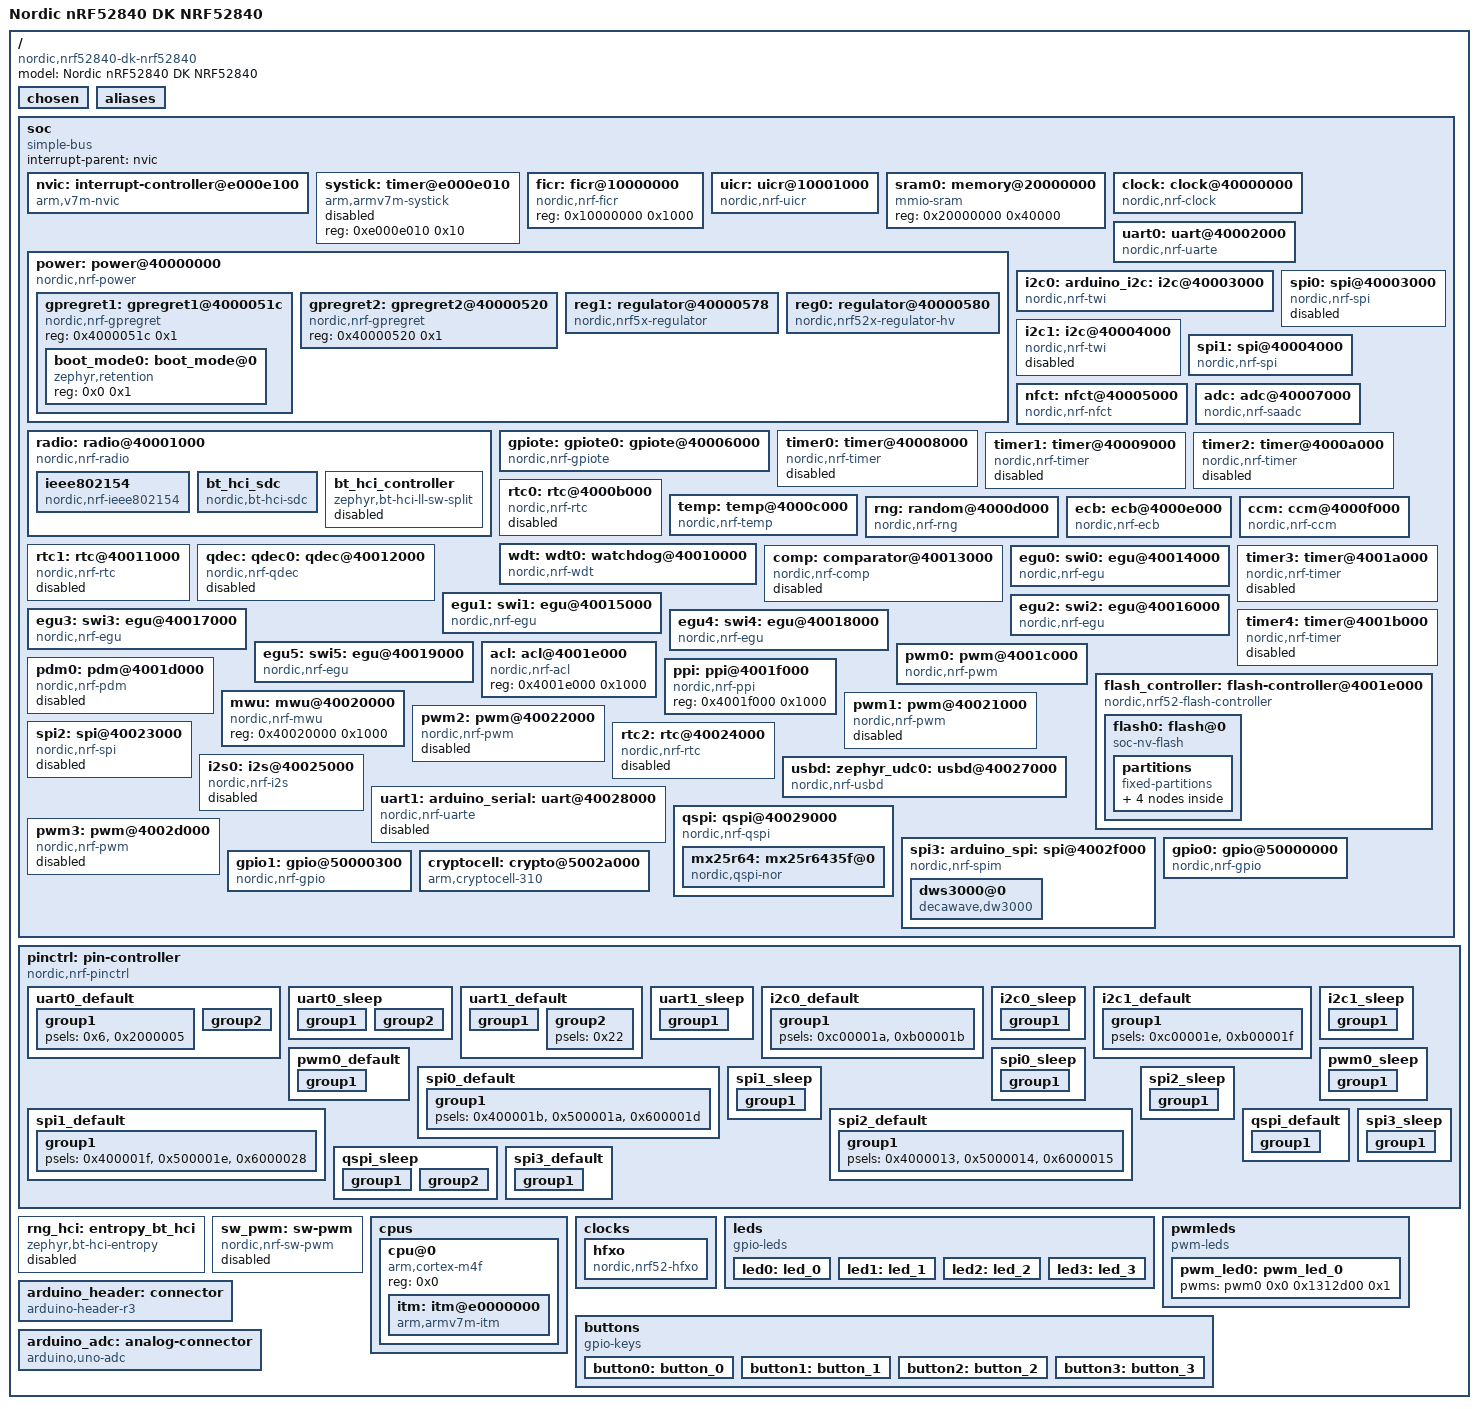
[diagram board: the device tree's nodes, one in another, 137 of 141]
/dts-v1/;

/* node '/' defined in zephyr\dts\common\skeleton.dtsi:9 */
/ {
	#address-cells = < 0x1 >;                   /* in zephyr\dts\common\skeleton.dtsi:10 */
	#size-cells = < 0x1 >;                      /* in zephyr\dts\common\skeleton.dtsi:11 */
	model = "Nordic nRF52840 DK NRF52840";      /* in zephyr\boards\nordic\nrf52840dk\nrf52840dk_nrf52840.dts:15 */
	compatible = "nordic,nrf52840-dk-nrf52840"; /* in zephyr\boards\nordic\nrf52840dk\nrf52840dk_nrf52840.dts:16 */

	/* node '/chosen' defined in zephyr\dts\common\skeleton.dtsi:13 */
	chosen {
		zephyr,bt-hci = &bt_hci_sdc;                 /* in zephyr\dts\arm\nordic\nrf52840.dtsi:14 */
		zephyr,entropy = &cryptocell;                /* in zephyr\dts\arm\nordic\nrf52840.dtsi:15 */
		zephyr,flash-controller = &flash_controller; /* in zephyr\dts\arm\nordic\nrf52840.dtsi:16 */
		zephyr,sram = &sram0;                        /* in zephyr\dts\vendor\nordic\nrf52840_partition.dtsi:9 */
		zephyr,flash = &flash0;                      /* in zephyr\dts\vendor\nordic\nrf52840_partition.dtsi:10 */
		zephyr,code-partition = &slot0_partition;    /* in zephyr\dts\vendor\nordic\nrf52840_partition.dtsi:11 */
		zephyr,console = &uart0;                     /* in zephyr\boards\nordic\nrf52840dk\nrf52840dk_nrf52840.dts:19 */
		zephyr,shell-uart = &uart0;                  /* in zephyr\boards\nordic\nrf52840dk\nrf52840dk_nrf52840.dts:20 */
		zephyr,uart-mcumgr = &uart0;                 /* in zephyr\boards\nordic\nrf52840dk\nrf52840dk_nrf52840.dts:21 */
		zephyr,bt-mon-uart = &uart0;                 /* in zephyr\boards\nordic\nrf52840dk\nrf52840dk_nrf52840.dts:22 */
		zephyr,bt-c2h-uart = &uart0;                 /* in zephyr\boards\nordic\nrf52840dk\nrf52840dk_nrf52840.dts:23 */
		zephyr,ieee802154 = &ieee802154;             /* in zephyr\boards\nordic\nrf52840dk\nrf52840dk_nrf52840.dts:24 */
		zephyr,boot-mode = &boot_mode0;              /* in zephyr\boards\nordic\nrf52840dk\nrf52840dk_nrf52840.dts:25 */
	};

	/* node '/aliases' defined in zephyr\dts\common\skeleton.dtsi:15 */
	aliases {
		led0 = &led0;               /* in zephyr\boards\nordic\nrf52840dk\nrf52840dk_nrf52840.dts:130 */
		led1 = &led1;               /* in zephyr\boards\nordic\nrf52840dk\nrf52840dk_nrf52840.dts:131 */
		led2 = &led2;               /* in zephyr\boards\nordic\nrf52840dk\nrf52840dk_nrf52840.dts:132 */
		led3 = &led3;               /* in zephyr\boards\nordic\nrf52840dk\nrf52840dk_nrf52840.dts:133 */
		pwm-led0 = &pwm_led0;       /* in zephyr\boards\nordic\nrf52840dk\nrf52840dk_nrf52840.dts:134 */
		sw0 = &button0;             /* in zephyr\boards\nordic\nrf52840dk\nrf52840dk_nrf52840.dts:135 */
		sw1 = &button1;             /* in zephyr\boards\nordic\nrf52840dk\nrf52840dk_nrf52840.dts:136 */
		sw2 = &button2;             /* in zephyr\boards\nordic\nrf52840dk\nrf52840dk_nrf52840.dts:137 */
		sw3 = &button3;             /* in zephyr\boards\nordic\nrf52840dk\nrf52840dk_nrf52840.dts:138 */
		mcuboot-button0 = &button0; /* in zephyr\boards\nordic\nrf52840dk\nrf52840dk_nrf52840.dts:139 */
		mcuboot-led0 = &led0;       /* in zephyr\boards\nordic\nrf52840dk\nrf52840dk_nrf52840.dts:140 */
		watchdog0 = &wdt0;          /* in zephyr\boards\nordic\nrf52840dk\nrf52840dk_nrf52840.dts:141 */
	};

	/* node '/soc' defined in zephyr\dts\arm\armv7-m.dtsi:6 */
	soc {
		#address-cells = < 0x1 >;     /* in zephyr\dts\arm\armv7-m.dtsi:7 */
		#size-cells = < 0x1 >;        /* in zephyr\dts\arm\armv7-m.dtsi:8 */
		interrupt-parent = < &nvic >; /* in zephyr\dts\arm\armv7-m.dtsi:10 */
		ranges;                       /* in zephyr\dts\arm\armv7-m.dtsi:11 */
		compatible = "simple-bus";    /* in zephyr\dts\arm\nordic\nrf52840_qiaa.dtsi:30 */

		/* node '/soc/interrupt-controller@e000e100' defined in zephyr\dts\arm\armv7-m.dtsi:13 */
		nvic: interrupt-controller@e000e100 {
			#address-cells = < 0x1 >;            /* in zephyr\dts\arm\armv7-m.dtsi:14 */
			compatible = "arm,v7m-nvic";         /* in zephyr\dts\arm\armv7-m.dtsi:15 */
			reg = < 0xe000e100 0xc00 >;          /* in zephyr\dts\arm\armv7-m.dtsi:16 */
			interrupt-controller;                /* in zephyr\dts\arm\armv7-m.dtsi:17 */
			#interrupt-cells = < 0x2 >;          /* in zephyr\dts\arm\armv7-m.dtsi:18 */
			arm,num-irq-priority-bits = < 0x3 >; /* in zephyr\dts\arm\nordic\nrf52840.dtsi:590 */
			phandle = < 0x1 >;                   /* in zephyr\dts\arm\armv7-m.dtsi:10 */
		};

		/* node '/soc/timer@e000e010' defined in zephyr\dts\arm\armv7-m.dtsi:21 */
		systick: timer@e000e010 {
			compatible = "arm,armv7m-systick"; /* in zephyr\dts\arm\armv7-m.dtsi:22 */
			reg = < 0xe000e010 0x10 >;         /* in zephyr\dts\arm\armv7-m.dtsi:23 */
			status = "disabled";               /* in zephyr\dts\arm\nordic\nrf52840.dtsi:595 */
		};

		/* node '/soc/ficr@10000000' defined in zephyr\dts\arm\nordic\nrf52840.dtsi:48 */
		ficr: ficr@10000000 {
			compatible = "nordic,nrf-ficr"; /* in zephyr\dts\arm\nordic\nrf52840.dtsi:49 */
			reg = < 0x10000000 0x1000 >;    /* in zephyr\dts\arm\nordic\nrf52840.dtsi:50 */
			#nordic,ficr-cells = < 0x1 >;   /* in zephyr\dts\arm\nordic\nrf52840.dtsi:51 */
			status = "okay";                /* in zephyr\dts\arm\nordic\nrf52840.dtsi:52 */
		};

		/* node '/soc/uicr@10001000' defined in zephyr\dts\arm\nordic\nrf52840.dtsi:55 */
		uicr: uicr@10001000 {
			compatible = "nordic,nrf-uicr";     /* in zephyr\dts\arm\nordic\nrf52840.dtsi:56 */
			reg = < 0x10001000 0x1000 >;        /* in zephyr\dts\arm\nordic\nrf52840.dtsi:57 */
			ranges = < 0x0 0x10001000 0x1000 >; /* in zephyr\dts\arm\nordic\nrf52840.dtsi:58 */
			status = "okay";                    /* in zephyr\dts\arm\nordic\nrf52840.dtsi:59 */
			#address-cells = < 0x1 >;           /* in zephyr\dts\arm\nordic\nrf52840.dtsi:60 */
			#size-cells = < 0x1 >;              /* in zephyr\dts\arm\nordic\nrf52840.dtsi:61 */
			gpio-as-nreset;                     /* in zephyr\boards\nordic\nrf52840dk\nrf52840dk_nrf52840.dts:158 */
		};

		/* node '/soc/memory@20000000' defined in zephyr\dts\arm\nordic\nrf52840.dtsi:64 */
		sram0: memory@20000000 {
			compatible = "mmio-sram";            /* in zephyr\dts\arm\nordic\nrf52840.dtsi:65 */
			#address-cells = < 0x1 >;            /* in zephyr\dts\arm\nordic\nrf52840.dtsi:66 */
			#size-cells = < 0x1 >;               /* in zephyr\dts\arm\nordic\nrf52840.dtsi:67 */
			reg = < 0x20000000 0x40000 >;        /* in zephyr\dts\arm\nordic\nrf52840_qiaa.dtsi:15 */
			ranges = < 0x0 0x20000000 0x40000 >; /* in zephyr\dts\arm\nordic\nrf52840_qiaa.dtsi:16 */
		};

		/* node '/soc/clock@40000000' defined in zephyr\dts\arm\nordic\nrf52840.dtsi:70 */
		clock: clock@40000000 {
			compatible = "nordic,nrf-clock"; /* in zephyr\dts\arm\nordic\nrf52840.dtsi:71 */
			reg = < 0x40000000 0x1000 >;     /* in zephyr\dts\arm\nordic\nrf52840.dtsi:72 */
			interrupts = < 0x0 0x1 >;        /* in zephyr\dts\arm\nordic\nrf52840.dtsi:73 */
			status = "okay";                 /* in zephyr\dts\arm\nordic\nrf52840.dtsi:74 */
		};

		/* node '/soc/power@40000000' defined in zephyr\dts\arm\nordic\nrf52840.dtsi:77 */
		power: power@40000000 {
			compatible = "nordic,nrf-power"; /* in zephyr\dts\arm\nordic\nrf52840.dtsi:78 */
			reg = < 0x40000000 0x1000 >;     /* in zephyr\dts\arm\nordic\nrf52840.dtsi:79 */
			interrupts = < 0x0 0x1 >;        /* in zephyr\dts\arm\nordic\nrf52840.dtsi:80 */
			status = "okay";                 /* in zephyr\dts\arm\nordic\nrf52840.dtsi:81 */
			#address-cells = < 0x1 >;        /* in zephyr\dts\arm\nordic\nrf52840.dtsi:82 */
			#size-cells = < 0x1 >;           /* in zephyr\dts\arm\nordic\nrf52840.dtsi:83 */

			/* node '/soc/power@40000000/gpregret1@4000051c' defined in zephyr\dts\arm\nordic\nrf52840.dtsi:85 */
			gpregret1: gpregret1@4000051c {
				#address-cells = < 0x1 >;           /* in zephyr\dts\arm\nordic\nrf52840.dtsi:86 */
				#size-cells = < 0x1 >;              /* in zephyr\dts\arm\nordic\nrf52840.dtsi:87 */
				compatible = "nordic,nrf-gpregret"; /* in zephyr\dts\arm\nordic\nrf52840.dtsi:88 */
				reg = < 0x4000051c 0x1 >;           /* in zephyr\dts\arm\nordic\nrf52840.dtsi:89 */
				status = "okay";                    /* in zephyr\boards\nordic\nrf52840dk\nrf52840dk_nrf52840.dts:294 */

				/* node '/soc/power@40000000/gpregret1@4000051c/boot_mode@0' defined in zephyr\boards\nordic\nrf52840dk\nrf52840dk_nrf52840.dts:296 */
				boot_mode0: boot_mode@0 {
					compatible = "zephyr,retention"; /* in zephyr\boards\nordic\nrf52840dk\nrf52840dk_nrf52840.dts:297 */
					status = "okay";                 /* in zephyr\boards\nordic\nrf52840dk\nrf52840dk_nrf52840.dts:298 */
					reg = < 0x0 0x1 >;               /* in zephyr\boards\nordic\nrf52840dk\nrf52840dk_nrf52840.dts:299 */
				};
			};

			/* node '/soc/power@40000000/gpregret2@40000520' defined in zephyr\dts\arm\nordic\nrf52840.dtsi:93 */
			gpregret2: gpregret2@40000520 {
				#address-cells = < 0x1 >;           /* in zephyr\dts\arm\nordic\nrf52840.dtsi:94 */
				#size-cells = < 0x1 >;              /* in zephyr\dts\arm\nordic\nrf52840.dtsi:95 */
				compatible = "nordic,nrf-gpregret"; /* in zephyr\dts\arm\nordic\nrf52840.dtsi:96 */
				reg = < 0x40000520 0x1 >;           /* in zephyr\dts\arm\nordic\nrf52840.dtsi:97 */
				status = "okay";                    /* in zephyr\dts\arm\nordic\nrf52840.dtsi:98 */
			};

			/* node '/soc/power@40000000/regulator@40000578' defined in zephyr\dts\arm\nordic\nrf52840.dtsi:101 */
			reg1: regulator@40000578 {
				compatible = "nordic,nrf5x-regulator"; /* in zephyr\dts\arm\nordic\nrf52840.dtsi:102 */
				reg = < 0x40000578 0x1 >;              /* in zephyr\dts\arm\nordic\nrf52840.dtsi:103 */
				regulator-name = "REG1";               /* in zephyr\dts\arm\nordic\nrf52840.dtsi:104 */
				regulator-initial-mode = < 0x1 >;      /* in zephyr\boards\nordic\nrf52840dk\nrf52840dk_nrf52840.dts:150 */
			};

			/* node '/soc/power@40000000/regulator@40000580' defined in zephyr\dts\arm\nordic\nrf52840_qiaa.dtsi:20 */
			reg0: regulator@40000580 {
				compatible = "nordic,nrf52x-regulator-hv"; /* in zephyr\dts\arm\nordic\nrf52840_qiaa.dtsi:21 */
				reg = < 0x40000580 0x1 >;                  /* in zephyr\dts\arm\nordic\nrf52840_qiaa.dtsi:22 */
				regulator-name = "REG0";                   /* in zephyr\dts\arm\nordic\nrf52840_qiaa.dtsi:23 */
				status = "okay";                           /* in zephyr\boards\nordic\nrf52840dk\nrf52840dk_nrf52840.dts:146 */
			};
		};

		/* node '/soc/radio@40001000' defined in zephyr\dts\arm\nordic\nrf52840.dtsi:109 */
		radio: radio@40001000 {
			compatible = "nordic,nrf-radio"; /* in zephyr\dts\arm\nordic\nrf52840.dtsi:110 */
			reg = < 0x40001000 0x1000 >;     /* in zephyr\dts\arm\nordic\nrf52840.dtsi:111 */
			interrupts = < 0x1 0x1 >;        /* in zephyr\dts\arm\nordic\nrf52840.dtsi:112 */
			status = "okay";                 /* in zephyr\dts\arm\nordic\nrf52840.dtsi:113 */
			ieee802154-supported;            /* in zephyr\dts\arm\nordic\nrf52840.dtsi:114 */
			ble-2mbps-supported;             /* in zephyr\dts\arm\nordic\nrf52840.dtsi:115 */
			ble-coded-phy-supported;         /* in zephyr\dts\arm\nordic\nrf52840.dtsi:116 */
			radio-tx-high-power-supported;   /* in zephyr\dts\arm\nordic\nrf52840.dtsi:117 */

			/* node '/soc/radio@40001000/ieee802154' defined in zephyr\dts\arm\nordic\nrf52840.dtsi:119 */
			ieee802154: ieee802154 {
				compatible = "nordic,nrf-ieee802154"; /* in zephyr\dts\arm\nordic\nrf52840.dtsi:120 */
				status = "okay";                      /* in zephyr\boards\nordic\nrf52840dk\nrf52840dk_nrf52840.dts:285 */
			};

			/* node '/soc/radio@40001000/bt_hci_sdc' defined in zephyr\dts\arm\nordic\nrf52840.dtsi:124 */
			bt_hci_sdc: bt_hci_sdc {
				compatible = "nordic,bt-hci-sdc"; /* in zephyr\dts\arm\nordic\nrf52840.dtsi:125 */
				status = "okay";                  /* in zephyr\dts\arm\nordic\nrf52840.dtsi:126 */
			};

			/* node '/soc/radio@40001000/bt_hci_controller' defined in zephyr\dts\arm\nordic\nrf52840.dtsi:128 */
			bt_hci_controller: bt_hci_controller {
				compatible = "zephyr,bt-hci-ll-sw-split"; /* in zephyr\dts\arm\nordic\nrf52840.dtsi:129 */
				status = "disabled";                      /* in zephyr\dts\arm\nordic\nrf52840.dtsi:130 */
			};
		};

		/* node '/soc/uart@40002000' defined in zephyr\dts\arm\nordic\nrf52840.dtsi:134 */
		uart0: uart@40002000 {
			reg = < 0x40002000 0x1000 >;     /* in zephyr\dts\arm\nordic\nrf52840.dtsi:138 */
			interrupts = < 0x2 0x1 >;        /* in zephyr\dts\arm\nordic\nrf52840.dtsi:139 */
			compatible = "nordic,nrf-uarte"; /* in zephyr\boards\nordic\nrf52840dk\nrf52840dk_nrf52840.dts:186 */
			status = "okay";                 /* in zephyr\boards\nordic\nrf52840dk\nrf52840dk_nrf52840.dts:187 */
			current-speed = < 0x1c200 >;     /* in zephyr\boards\nordic\nrf52840dk\nrf52840dk_nrf52840.dts:188 */
			pinctrl-0 = < &uart0_default >;  /* in zephyr\boards\nordic\nrf52840dk\nrf52840dk_nrf52840.dts:189 */
			pinctrl-1 = < &uart0_sleep >;    /* in zephyr\boards\nordic\nrf52840dk\nrf52840dk_nrf52840.dts:190 */
			pinctrl-names = "default",
			                "sleep";         /* in zephyr\boards\nordic\nrf52840dk\nrf52840dk_nrf52840.dts:191 */
		};

		/* node '/soc/i2c@40003000' defined in zephyr\dts\arm\nordic\nrf52840.dtsi:143 */
		i2c0: arduino_i2c: i2c@40003000 {
			#address-cells = < 0x1 >;       /* in zephyr\dts\arm\nordic\nrf52840.dtsi:152 */
			#size-cells = < 0x0 >;          /* in zephyr\dts\arm\nordic\nrf52840.dtsi:153 */
			reg = < 0x40003000 0x1000 >;    /* in zephyr\dts\arm\nordic\nrf52840.dtsi:154 */
			interrupts = < 0x3 0x1 >;       /* in zephyr\dts\arm\nordic\nrf52840.dtsi:155 */
			easydma-maxcnt-bits = < 0x10 >; /* in zephyr\dts\arm\nordic\nrf52840.dtsi:156 */
			zephyr,pm-device-runtime-auto;  /* in zephyr\dts\arm\nordic\nrf52840.dtsi:158 */
			compatible = "nordic,nrf-twi";  /* in zephyr\boards\nordic\nrf52840dk\nrf52840dk_nrf52840.dts:202 */
			status = "okay";                /* in zephyr\boards\nordic\nrf52840dk\nrf52840dk_nrf52840.dts:203 */
			pinctrl-0 = < &i2c0_default >;  /* in zephyr\boards\nordic\nrf52840dk\nrf52840dk_nrf52840.dts:204 */
			pinctrl-1 = < &i2c0_sleep >;    /* in zephyr\boards\nordic\nrf52840dk\nrf52840dk_nrf52840.dts:205 */
			pinctrl-names = "default",
			                "sleep";        /* in zephyr\boards\nordic\nrf52840dk\nrf52840dk_nrf52840.dts:206 */
		};

		/* node '/soc/spi@40003000' defined in zephyr\dts\arm\nordic\nrf52840.dtsi:161 */
		spi0: spi@40003000 {
			#address-cells = < 0x1 >;       /* in zephyr\dts\arm\nordic\nrf52840.dtsi:170 */
			#size-cells = < 0x0 >;          /* in zephyr\dts\arm\nordic\nrf52840.dtsi:171 */
			reg = < 0x40003000 0x1000 >;    /* in zephyr\dts\arm\nordic\nrf52840.dtsi:172 */
			interrupts = < 0x3 0x1 >;       /* in zephyr\dts\arm\nordic\nrf52840.dtsi:173 */
			max-frequency = < 0x7a1200 >;   /* in zephyr\dts\arm\nordic\nrf52840.dtsi:174 */
			easydma-maxcnt-bits = < 0x10 >; /* in zephyr\dts\arm\nordic\nrf52840.dtsi:175 */
			status = "disabled";            /* in zephyr\dts\arm\nordic\nrf52840.dtsi:176 */
			compatible = "nordic,nrf-spi";  /* in zephyr\boards\nordic\nrf52840dk\nrf52840dk_nrf52840.dts:226 */
			pinctrl-0 = < &spi0_default >;  /* in zephyr\boards\nordic\nrf52840dk\nrf52840dk_nrf52840.dts:229 */
			pinctrl-1 = < &spi0_sleep >;    /* in zephyr\boards\nordic\nrf52840dk\nrf52840dk_nrf52840.dts:230 */
			pinctrl-names = "default",
			                "sleep";        /* in zephyr\boards\nordic\nrf52840dk\nrf52840dk_nrf52840.dts:231 */
		};

		/* node '/soc/i2c@40004000' defined in zephyr\dts\arm\nordic\nrf52840.dtsi:179 */
		i2c1: i2c@40004000 {
			#address-cells = < 0x1 >;       /* in zephyr\dts\arm\nordic\nrf52840.dtsi:188 */
			#size-cells = < 0x0 >;          /* in zephyr\dts\arm\nordic\nrf52840.dtsi:189 */
			reg = < 0x40004000 0x1000 >;    /* in zephyr\dts\arm\nordic\nrf52840.dtsi:190 */
			interrupts = < 0x4 0x1 >;       /* in zephyr\dts\arm\nordic\nrf52840.dtsi:191 */
			easydma-maxcnt-bits = < 0x10 >; /* in zephyr\dts\arm\nordic\nrf52840.dtsi:192 */
			status = "disabled";            /* in zephyr\dts\arm\nordic\nrf52840.dtsi:193 */
			zephyr,pm-device-runtime-auto;  /* in zephyr\dts\arm\nordic\nrf52840.dtsi:194 */
			compatible = "nordic,nrf-twi";  /* in zephyr\boards\nordic\nrf52840dk\nrf52840dk_nrf52840.dts:210 */
			pinctrl-0 = < &i2c1_default >;  /* in zephyr\boards\nordic\nrf52840dk\nrf52840dk_nrf52840.dts:213 */
			pinctrl-1 = < &i2c1_sleep >;    /* in zephyr\boards\nordic\nrf52840dk\nrf52840dk_nrf52840.dts:214 */
			pinctrl-names = "default",
			                "sleep";        /* in zephyr\boards\nordic\nrf52840dk\nrf52840dk_nrf52840.dts:215 */
		};

		/* node '/soc/spi@40004000' defined in zephyr\dts\arm\nordic\nrf52840.dtsi:197 */
		spi1: spi@40004000 {
			#address-cells = < 0x1 >;       /* in zephyr\dts\arm\nordic\nrf52840.dtsi:206 */
			#size-cells = < 0x0 >;          /* in zephyr\dts\arm\nordic\nrf52840.dtsi:207 */
			reg = < 0x40004000 0x1000 >;    /* in zephyr\dts\arm\nordic\nrf52840.dtsi:208 */
			interrupts = < 0x4 0x1 >;       /* in zephyr\dts\arm\nordic\nrf52840.dtsi:209 */
			max-frequency = < 0x7a1200 >;   /* in zephyr\dts\arm\nordic\nrf52840.dtsi:210 */
			easydma-maxcnt-bits = < 0x10 >; /* in zephyr\dts\arm\nordic\nrf52840.dtsi:211 */
			compatible = "nordic,nrf-spi";  /* in zephyr\boards\nordic\nrf52840dk\nrf52840dk_nrf52840.dts:235 */
			status = "okay";                /* in zephyr\boards\nordic\nrf52840dk\nrf52840dk_nrf52840.dts:236 */
			pinctrl-0 = < &spi1_default >;  /* in zephyr\boards\nordic\nrf52840dk\nrf52840dk_nrf52840.dts:237 */
			pinctrl-1 = < &spi1_sleep >;    /* in zephyr\boards\nordic\nrf52840dk\nrf52840dk_nrf52840.dts:238 */
			pinctrl-names = "default",
			                "sleep";        /* in zephyr\boards\nordic\nrf52840dk\nrf52840dk_nrf52840.dts:239 */
		};

		/* node '/soc/nfct@40005000' defined in zephyr\dts\arm\nordic\nrf52840.dtsi:215 */
		nfct: nfct@40005000 {
			compatible = "nordic,nrf-nfct"; /* in zephyr\dts\arm\nordic\nrf52840.dtsi:216 */
			reg = < 0x40005000 0x1000 >;    /* in zephyr\dts\arm\nordic\nrf52840.dtsi:217 */
			interrupts = < 0x5 0x1 >;       /* in zephyr\dts\arm\nordic\nrf52840.dtsi:218 */
			status = "okay";                /* in zephyr\boards\nordic\nrf52840dk\nrf52840dk_nrf52840.dts:166 */
		};

		/* node '/soc/gpiote@40006000' defined in zephyr\dts\arm\nordic\nrf52840.dtsi:222 */
		gpiote: gpiote0: gpiote@40006000 {
			compatible = "nordic,nrf-gpiote"; /* in zephyr\dts\arm\nordic\nrf52840.dtsi:223 */
			reg = < 0x40006000 0x1000 >;      /* in zephyr\dts\arm\nordic\nrf52840.dtsi:224 */
			interrupts = < 0x6 0x5 >;         /* in zephyr\dts\arm\nordic\nrf52840.dtsi:225 */
			instance = < 0x0 >;               /* in zephyr\dts\arm\nordic\nrf52840.dtsi:227 */
			status = "okay";                  /* in zephyr\boards\nordic\nrf52840dk\nrf52840dk_nrf52840.dts:162 */
			phandle = < 0x17 >;               /* in zephyr\dts\arm\nordic\nrf52840.dtsi:564 */
		};

		/* node '/soc/adc@40007000' defined in zephyr\dts\arm\nordic\nrf52840.dtsi:230 */
		adc: adc@40007000 {
			compatible = "nordic,nrf-saadc"; /* in zephyr\dts\arm\nordic\nrf52840.dtsi:231 */
			reg = < 0x40007000 0x1000 >;     /* in zephyr\dts\arm\nordic\nrf52840.dtsi:232 */
			interrupts = < 0x7 0x1 >;        /* in zephyr\dts\arm\nordic\nrf52840.dtsi:233 */
			#io-channel-cells = < 0x1 >;     /* in zephyr\dts\arm\nordic\nrf52840.dtsi:235 */
			zephyr,pm-device-runtime-auto;   /* in zephyr\dts\arm\nordic\nrf52840.dtsi:236 */
			status = "okay";                 /* in zephyr\boards\nordic\nrf52840dk\nrf52840dk_nrf52840.dts:154 */
			phandle = < 0x1c >;              /* in zephyr\boards\nordic\nrf52840dk\nrf52840dk_nrf52840.dts:120 */
		};

		/* node '/soc/timer@40008000' defined in zephyr\dts\arm\nordic\nrf52840.dtsi:239 */
		timer0: timer@40008000 {
			compatible = "nordic,nrf-timer"; /* in zephyr\dts\arm\nordic\nrf52840.dtsi:240 */
			status = "disabled";             /* in zephyr\dts\arm\nordic\nrf52840.dtsi:241 */
			reg = < 0x40008000 0x1000 >;     /* in zephyr\dts\arm\nordic\nrf52840.dtsi:242 */
			cc-num = < 0x4 >;                /* in zephyr\dts\arm\nordic\nrf52840.dtsi:243 */
			max-bit-width = < 0x20 >;        /* in zephyr\dts\arm\nordic\nrf52840.dtsi:244 */
			interrupts = < 0x8 0x1 >;        /* in zephyr\dts\arm\nordic\nrf52840.dtsi:245 */
			prescaler = < 0x0 >;             /* in zephyr\dts\arm\nordic\nrf52840.dtsi:246 */
		};

		/* node '/soc/timer@40009000' defined in zephyr\dts\arm\nordic\nrf52840.dtsi:249 */
		timer1: timer@40009000 {
			compatible = "nordic,nrf-timer"; /* in zephyr\dts\arm\nordic\nrf52840.dtsi:250 */
			status = "disabled";             /* in zephyr\dts\arm\nordic\nrf52840.dtsi:251 */
			reg = < 0x40009000 0x1000 >;     /* in zephyr\dts\arm\nordic\nrf52840.dtsi:252 */
			cc-num = < 0x4 >;                /* in zephyr\dts\arm\nordic\nrf52840.dtsi:253 */
			max-bit-width = < 0x20 >;        /* in zephyr\dts\arm\nordic\nrf52840.dtsi:254 */
			interrupts = < 0x9 0x1 >;        /* in zephyr\dts\arm\nordic\nrf52840.dtsi:255 */
			prescaler = < 0x0 >;             /* in zephyr\dts\arm\nordic\nrf52840.dtsi:256 */
			phandle = < 0x18 >;              /* in zephyr\dts\vendor\nordic\nrf_common.dtsi:42 */
		};

		/* node '/soc/timer@4000a000' defined in zephyr\dts\arm\nordic\nrf52840.dtsi:259 */
		timer2: timer@4000a000 {
			compatible = "nordic,nrf-timer"; /* in zephyr\dts\arm\nordic\nrf52840.dtsi:260 */
			status = "disabled";             /* in zephyr\dts\arm\nordic\nrf52840.dtsi:261 */
			reg = < 0x4000a000 0x1000 >;     /* in zephyr\dts\arm\nordic\nrf52840.dtsi:262 */
			cc-num = < 0x4 >;                /* in zephyr\dts\arm\nordic\nrf52840.dtsi:263 */
			max-bit-width = < 0x20 >;        /* in zephyr\dts\arm\nordic\nrf52840.dtsi:264 */
			interrupts = < 0xa 0x1 >;        /* in zephyr\dts\arm\nordic\nrf52840.dtsi:265 */
			prescaler = < 0x0 >;             /* in zephyr\dts\arm\nordic\nrf52840.dtsi:266 */
		};

		/* node '/soc/rtc@4000b000' defined in zephyr\dts\arm\nordic\nrf52840.dtsi:269 */
		rtc0: rtc@4000b000 {
			compatible = "nordic,nrf-rtc"; /* in zephyr\dts\arm\nordic\nrf52840.dtsi:270 */
			reg = < 0x4000b000 0x1000 >;   /* in zephyr\dts\arm\nordic\nrf52840.dtsi:271 */
			cc-num = < 0x3 >;              /* in zephyr\dts\arm\nordic\nrf52840.dtsi:272 */
			interrupts = < 0xb 0x1 >;      /* in zephyr\dts\arm\nordic\nrf52840.dtsi:273 */
			status = "disabled";           /* in zephyr\dts\arm\nordic\nrf52840.dtsi:274 */
			clock-frequency = < 0x8000 >;  /* in zephyr\dts\arm\nordic\nrf52840.dtsi:275 */
			prescaler = < 0x1 >;           /* in zephyr\dts\arm\nordic\nrf52840.dtsi:276 */
		};

		/* node '/soc/temp@4000c000' defined in zephyr\dts\arm\nordic\nrf52840.dtsi:279 */
		temp: temp@4000c000 {
			compatible = "nordic,nrf-temp"; /* in zephyr\dts\arm\nordic\nrf52840.dtsi:280 */
			reg = < 0x4000c000 0x1000 >;    /* in zephyr\dts\arm\nordic\nrf52840.dtsi:281 */
			interrupts = < 0xc 0x1 >;       /* in zephyr\dts\arm\nordic\nrf52840.dtsi:282 */
			status = "okay";                /* in zephyr\dts\arm\nordic\nrf52840.dtsi:283 */
		};

		/* node '/soc/random@4000d000' defined in zephyr\dts\arm\nordic\nrf52840.dtsi:286 */
		rng: random@4000d000 {
			compatible = "nordic,nrf-rng"; /* in zephyr\dts\arm\nordic\nrf52840.dtsi:287 */
			reg = < 0x4000d000 0x1000 >;   /* in zephyr\dts\arm\nordic\nrf52840.dtsi:288 */
			interrupts = < 0xd 0x1 >;      /* in zephyr\dts\arm\nordic\nrf52840.dtsi:289 */
			status = "okay";               /* in zephyr\dts\arm\nordic\nrf52840.dtsi:290 */
		};

		/* node '/soc/ecb@4000e000' defined in zephyr\dts\arm\nordic\nrf52840.dtsi:293 */
		ecb: ecb@4000e000 {
			compatible = "nordic,nrf-ecb"; /* in zephyr\dts\arm\nordic\nrf52840.dtsi:294 */
			reg = < 0x4000e000 0x1000 >;   /* in zephyr\dts\arm\nordic\nrf52840.dtsi:295 */
			interrupts = < 0xe 0x1 >;      /* in zephyr\dts\arm\nordic\nrf52840.dtsi:296 */
			status = "okay";               /* in zephyr\dts\arm\nordic\nrf52840.dtsi:297 */
		};

		/* node '/soc/ccm@4000f000' defined in zephyr\dts\arm\nordic\nrf52840.dtsi:300 */
		ccm: ccm@4000f000 {
			compatible = "nordic,nrf-ccm"; /* in zephyr\dts\arm\nordic\nrf52840.dtsi:301 */
			reg = < 0x4000f000 0x1000 >;   /* in zephyr\dts\arm\nordic\nrf52840.dtsi:302 */
			interrupts = < 0xf 0x1 >;      /* in zephyr\dts\arm\nordic\nrf52840.dtsi:303 */
			length-field-length-8-bits;    /* in zephyr\dts\arm\nordic\nrf52840.dtsi:304 */
			status = "okay";               /* in zephyr\dts\arm\nordic\nrf52840.dtsi:305 */
		};

		/* node '/soc/watchdog@40010000' defined in zephyr\dts\arm\nordic\nrf52840.dtsi:308 */
		wdt: wdt0: watchdog@40010000 {
			compatible = "nordic,nrf-wdt"; /* in zephyr\dts\arm\nordic\nrf52840.dtsi:309 */
			reg = < 0x40010000 0x1000 >;   /* in zephyr\dts\arm\nordic\nrf52840.dtsi:310 */
			interrupts = < 0x10 0x1 >;     /* in zephyr\dts\arm\nordic\nrf52840.dtsi:311 */
			status = "okay";               /* in zephyr\dts\arm\nordic\nrf52840.dtsi:312 */
		};

		/* node '/soc/rtc@40011000' defined in zephyr\dts\arm\nordic\nrf52840.dtsi:315 */
		rtc1: rtc@40011000 {
			compatible = "nordic,nrf-rtc"; /* in zephyr\dts\arm\nordic\nrf52840.dtsi:316 */
			reg = < 0x40011000 0x1000 >;   /* in zephyr\dts\arm\nordic\nrf52840.dtsi:317 */
			cc-num = < 0x4 >;              /* in zephyr\dts\arm\nordic\nrf52840.dtsi:318 */
			interrupts = < 0x11 0x1 >;     /* in zephyr\dts\arm\nordic\nrf52840.dtsi:319 */
			status = "disabled";           /* in zephyr\dts\arm\nordic\nrf52840.dtsi:320 */
			clock-frequency = < 0x8000 >;  /* in zephyr\dts\arm\nordic\nrf52840.dtsi:321 */
			prescaler = < 0x1 >;           /* in zephyr\dts\arm\nordic\nrf52840.dtsi:322 */
		};

		/* node '/soc/qdec@40012000' defined in zephyr\dts\arm\nordic\nrf52840.dtsi:325 */
		qdec: qdec0: qdec@40012000 {
			compatible = "nordic,nrf-qdec"; /* in zephyr\dts\arm\nordic\nrf52840.dtsi:326 */
			reg = < 0x40012000 0x1000 >;    /* in zephyr\dts\arm\nordic\nrf52840.dtsi:327 */
			interrupts = < 0x12 0x1 >;      /* in zephyr\dts\arm\nordic\nrf52840.dtsi:328 */
			status = "disabled";            /* in zephyr\dts\arm\nordic\nrf52840.dtsi:329 */
		};

		/* node '/soc/comparator@40013000' defined in zephyr\dts\arm\nordic\nrf52840.dtsi:332 */
		comp: comparator@40013000 {
			compatible = "nordic,nrf-comp"; /* in zephyr\dts\arm\nordic\nrf52840.dtsi:337 */
			reg = < 0x40013000 0x1000 >;    /* in zephyr\dts\arm\nordic\nrf52840.dtsi:338 */
			interrupts = < 0x13 0x1 >;      /* in zephyr\dts\arm\nordic\nrf52840.dtsi:339 */
			status = "disabled";            /* in zephyr\dts\arm\nordic\nrf52840.dtsi:340 */
		};

		/* node '/soc/egu@40014000' defined in zephyr\dts\arm\nordic\nrf52840.dtsi:343 */
		egu0: swi0: egu@40014000 {
			compatible = "nordic,nrf-egu",
			             "nordic,nrf-swi"; /* in zephyr\dts\arm\nordic\nrf52840.dtsi:344 */
			reg = < 0x40014000 0x1000 >;   /* in zephyr\dts\arm\nordic\nrf52840.dtsi:345 */
			interrupts = < 0x14 0x1 >;     /* in zephyr\dts\arm\nordic\nrf52840.dtsi:346 */
			status = "okay";               /* in zephyr\dts\arm\nordic\nrf52840.dtsi:347 */
		};

		/* node '/soc/egu@40015000' defined in zephyr\dts\arm\nordic\nrf52840.dtsi:350 */
		egu1: swi1: egu@40015000 {
			compatible = "nordic,nrf-egu",
			             "nordic,nrf-swi"; /* in zephyr\dts\arm\nordic\nrf52840.dtsi:351 */
			reg = < 0x40015000 0x1000 >;   /* in zephyr\dts\arm\nordic\nrf52840.dtsi:352 */
			interrupts = < 0x15 0x1 >;     /* in zephyr\dts\arm\nordic\nrf52840.dtsi:353 */
			status = "okay";               /* in zephyr\dts\arm\nordic\nrf52840.dtsi:354 */
		};

		/* node '/soc/egu@40016000' defined in zephyr\dts\arm\nordic\nrf52840.dtsi:357 */
		egu2: swi2: egu@40016000 {
			compatible = "nordic,nrf-egu",
			             "nordic,nrf-swi"; /* in zephyr\dts\arm\nordic\nrf52840.dtsi:358 */
			reg = < 0x40016000 0x1000 >;   /* in zephyr\dts\arm\nordic\nrf52840.dtsi:359 */
			interrupts = < 0x16 0x1 >;     /* in zephyr\dts\arm\nordic\nrf52840.dtsi:360 */
			status = "okay";               /* in zephyr\dts\arm\nordic\nrf52840.dtsi:361 */
		};

		/* node '/soc/egu@40017000' defined in zephyr\dts\arm\nordic\nrf52840.dtsi:364 */
		egu3: swi3: egu@40017000 {
			compatible = "nordic,nrf-egu",
			             "nordic,nrf-swi"; /* in zephyr\dts\arm\nordic\nrf52840.dtsi:365 */
			reg = < 0x40017000 0x1000 >;   /* in zephyr\dts\arm\nordic\nrf52840.dtsi:366 */
			interrupts = < 0x17 0x1 >;     /* in zephyr\dts\arm\nordic\nrf52840.dtsi:367 */
			status = "okay";               /* in zephyr\dts\arm\nordic\nrf52840.dtsi:368 */
		};

		/* node '/soc/egu@40018000' defined in zephyr\dts\arm\nordic\nrf52840.dtsi:371 */
		egu4: swi4: egu@40018000 {
			compatible = "nordic,nrf-egu",
			             "nordic,nrf-swi"; /* in zephyr\dts\arm\nordic\nrf52840.dtsi:372 */
			reg = < 0x40018000 0x1000 >;   /* in zephyr\dts\arm\nordic\nrf52840.dtsi:373 */
			interrupts = < 0x18 0x1 >;     /* in zephyr\dts\arm\nordic\nrf52840.dtsi:374 */
			status = "okay";               /* in zephyr\dts\arm\nordic\nrf52840.dtsi:375 */
		};

		/* node '/soc/egu@40019000' defined in zephyr\dts\arm\nordic\nrf52840.dtsi:378 */
		egu5: swi5: egu@40019000 {
			compatible = "nordic,nrf-egu",
			             "nordic,nrf-swi"; /* in zephyr\dts\arm\nordic\nrf52840.dtsi:379 */
			reg = < 0x40019000 0x1000 >;   /* in zephyr\dts\arm\nordic\nrf52840.dtsi:380 */
			interrupts = < 0x19 0x1 >;     /* in zephyr\dts\arm\nordic\nrf52840.dtsi:381 */
			status = "okay";               /* in zephyr\dts\arm\nordic\nrf52840.dtsi:382 */
		};

		/* node '/soc/timer@4001a000' defined in zephyr\dts\arm\nordic\nrf52840.dtsi:385 */
		timer3: timer@4001a000 {
			compatible = "nordic,nrf-timer"; /* in zephyr\dts\arm\nordic\nrf52840.dtsi:386 */
			status = "disabled";             /* in zephyr\dts\arm\nordic\nrf52840.dtsi:387 */
			reg = < 0x4001a000 0x1000 >;     /* in zephyr\dts\arm\nordic\nrf52840.dtsi:388 */
			cc-num = < 0x6 >;                /* in zephyr\dts\arm\nordic\nrf52840.dtsi:389 */
			max-bit-width = < 0x20 >;        /* in zephyr\dts\arm\nordic\nrf52840.dtsi:390 */
			interrupts = < 0x1a 0x1 >;       /* in zephyr\dts\arm\nordic\nrf52840.dtsi:391 */
			prescaler = < 0x0 >;             /* in zephyr\dts\arm\nordic\nrf52840.dtsi:392 */
		};

		/* node '/soc/timer@4001b000' defined in zephyr\dts\arm\nordic\nrf52840.dtsi:395 */
		timer4: timer@4001b000 {
			compatible = "nordic,nrf-timer"; /* in zephyr\dts\arm\nordic\nrf52840.dtsi:396 */
			status = "disabled";             /* in zephyr\dts\arm\nordic\nrf52840.dtsi:397 */
			reg = < 0x4001b000 0x1000 >;     /* in zephyr\dts\arm\nordic\nrf52840.dtsi:398 */
			cc-num = < 0x6 >;                /* in zephyr\dts\arm\nordic\nrf52840.dtsi:399 */
			max-bit-width = < 0x20 >;        /* in zephyr\dts\arm\nordic\nrf52840.dtsi:400 */
			interrupts = < 0x1b 0x1 >;       /* in zephyr\dts\arm\nordic\nrf52840.dtsi:401 */
			prescaler = < 0x0 >;             /* in zephyr\dts\arm\nordic\nrf52840.dtsi:402 */
		};

		/* node '/soc/pwm@4001c000' defined in zephyr\dts\arm\nordic\nrf52840.dtsi:405 */
		pwm0: pwm@4001c000 {
			compatible = "nordic,nrf-pwm"; /* in zephyr\dts\arm\nordic\nrf52840.dtsi:406 */
			reg = < 0x4001c000 0x1000 >;   /* in zephyr\dts\arm\nordic\nrf52840.dtsi:407 */
			interrupts = < 0x1c 0x1 >;     /* in zephyr\dts\arm\nordic\nrf52840.dtsi:408 */
			#pwm-cells = < 0x3 >;          /* in zephyr\dts\arm\nordic\nrf52840.dtsi:410 */
			status = "okay";               /* in zephyr\boards\nordic\nrf52840dk\nrf52840dk_nrf52840.dts:219 */
			pinctrl-0 = < &pwm0_default >; /* in zephyr\boards\nordic\nrf52840dk\nrf52840dk_nrf52840.dts:220 */
			pinctrl-1 = < &pwm0_sleep >;   /* in zephyr\boards\nordic\nrf52840dk\nrf52840dk_nrf52840.dts:221 */
			pinctrl-names = "default",
			                "sleep";       /* in zephyr\boards\nordic\nrf52840dk\nrf52840dk_nrf52840.dts:222 */
			phandle = < 0x1a >;            /* in zephyr\boards\nordic\nrf52840dk\nrf52840dk_nrf52840.dts:56 */
		};

		/* node '/soc/pdm@4001d000' defined in zephyr\dts\arm\nordic\nrf52840.dtsi:413 */
		pdm0: pdm@4001d000 {
			compatible = "nordic,nrf-pdm"; /* in zephyr\dts\arm\nordic\nrf52840.dtsi:414 */
			reg = < 0x4001d000 0x1000 >;   /* in zephyr\dts\arm\nordic\nrf52840.dtsi:415 */
			interrupts = < 0x1d 0x1 >;     /* in zephyr\dts\arm\nordic\nrf52840.dtsi:416 */
			status = "disabled";           /* in zephyr\dts\arm\nordic\nrf52840.dtsi:417 */
		};

		/* node '/soc/acl@4001e000' defined in zephyr\dts\arm\nordic\nrf52840.dtsi:420 */
		acl: acl@4001e000 {
			compatible = "nordic,nrf-acl"; /* in zephyr\dts\arm\nordic\nrf52840.dtsi:421 */
			reg = < 0x4001e000 0x1000 >;   /* in zephyr\dts\arm\nordic\nrf52840.dtsi:422 */
			status = "okay";               /* in zephyr\dts\arm\nordic\nrf52840.dtsi:423 */
		};

		/* node '/soc/flash-controller@4001e000' defined in zephyr\dts\arm\nordic\nrf52840.dtsi:426 */
		flash_controller: flash-controller@4001e000 {
			compatible = "nordic,nrf52-flash-controller"; /* in zephyr\dts\arm\nordic\nrf52840.dtsi:427 */
			reg = < 0x4001e000 0x1000 >;                  /* in zephyr\dts\arm\nordic\nrf52840.dtsi:428 */
			partial-erase;                                /* in zephyr\dts\arm\nordic\nrf52840.dtsi:429 */
			#address-cells = < 0x1 >;                     /* in zephyr\dts\arm\nordic\nrf52840.dtsi:431 */
			#size-cells = < 0x1 >;                        /* in zephyr\dts\arm\nordic\nrf52840.dtsi:432 */

			/* node '/soc/flash-controller@4001e000/flash@0' defined in zephyr\dts\arm\nordic\nrf52840.dtsi:434 */
			flash0: flash@0 {
				compatible = "soc-nv-flash";   /* in zephyr\dts\arm\nordic\nrf52840.dtsi:435 */
				erase-block-size = < 0x1000 >; /* in zephyr\dts\arm\nordic\nrf52840.dtsi:436 */
				write-block-size = < 0x4 >;    /* in zephyr\dts\arm\nordic\nrf52840.dtsi:437 */
				reg = < 0x0 0x100000 >;        /* in zephyr\dts\arm\nordic\nrf52840_qiaa.dtsi:11 */

				/* node '/soc/flash-controller@4001e000/flash@0/partitions' defined in zephyr\dts\vendor\nordic\nrf52840_partition.dtsi:16 */
				partitions {
					compatible = "fixed-partitions"; /* in zephyr\dts\vendor\nordic\nrf52840_partition.dtsi:17 */
					#address-cells = < 0x1 >;        /* in zephyr\dts\vendor\nordic\nrf52840_partition.dtsi:18 */
					#size-cells = < 0x1 >;           /* in zephyr\dts\vendor\nordic\nrf52840_partition.dtsi:19 */

					/* node '/soc/flash-controller@4001e000/flash@0/partitions/partition@0' defined in zephyr\dts\vendor\nordic\nrf52840_partition.dtsi:21 */
					boot_partition: partition@0 {
						label = "mcuboot";    /* in zephyr\dts\vendor\nordic\nrf52840_partition.dtsi:22 */
						reg = < 0x0 0xc000 >; /* in zephyr\dts\vendor\nordic\nrf52840_partition.dtsi:23 */
					};

					/* node '/soc/flash-controller@4001e000/flash@0/partitions/partition@c000' defined in zephyr\dts\vendor\nordic\nrf52840_partition.dtsi:26 */
					slot0_partition: partition@c000 {
						label = "image-0";        /* in zephyr\dts\vendor\nordic\nrf52840_partition.dtsi:27 */
						reg = < 0xc000 0x76000 >; /* in zephyr\dts\vendor\nordic\nrf52840_partition.dtsi:28 */
					};

					/* node '/soc/flash-controller@4001e000/flash@0/partitions/partition@82000' defined in zephyr\dts\vendor\nordic\nrf52840_partition.dtsi:31 */
					slot1_partition: partition@82000 {
						label = "image-1";         /* in zephyr\dts\vendor\nordic\nrf52840_partition.dtsi:32 */
						reg = < 0x82000 0x76000 >; /* in zephyr\dts\vendor\nordic\nrf52840_partition.dtsi:33 */
					};

					/* node '/soc/flash-controller@4001e000/flash@0/partitions/partition@f8000' defined in zephyr\dts\vendor\nordic\nrf52840_partition.dtsi:45 */
					storage_partition: partition@f8000 {
						label = "storage";        /* in zephyr\dts\vendor\nordic\nrf52840_partition.dtsi:46 */
						reg = < 0xf8000 0x8000 >; /* in zephyr\dts\vendor\nordic\nrf52840_partition.dtsi:47 */
					};
				};
			};
		};

		/* node '/soc/ppi@4001f000' defined in zephyr\dts\arm\nordic\nrf52840.dtsi:441 */
		ppi: ppi@4001f000 {
			compatible = "nordic,nrf-ppi"; /* in zephyr\dts\arm\nordic\nrf52840.dtsi:442 */
			reg = < 0x4001f000 0x1000 >;   /* in zephyr\dts\arm\nordic\nrf52840.dtsi:443 */
			status = "okay";               /* in zephyr\dts\arm\nordic\nrf52840.dtsi:444 */
		};

		/* node '/soc/mwu@40020000' defined in zephyr\dts\arm\nordic\nrf52840.dtsi:447 */
		mwu: mwu@40020000 {
			compatible = "nordic,nrf-mwu"; /* in zephyr\dts\arm\nordic\nrf52840.dtsi:448 */
			reg = < 0x40020000 0x1000 >;   /* in zephyr\dts\arm\nordic\nrf52840.dtsi:449 */
			status = "okay";               /* in zephyr\dts\arm\nordic\nrf52840.dtsi:450 */
		};

		/* node '/soc/pwm@40021000' defined in zephyr\dts\arm\nordic\nrf52840.dtsi:453 */
		pwm1: pwm@40021000 {
			compatible = "nordic,nrf-pwm"; /* in zephyr\dts\arm\nordic\nrf52840.dtsi:454 */
			reg = < 0x40021000 0x1000 >;   /* in zephyr\dts\arm\nordic\nrf52840.dtsi:455 */
			interrupts = < 0x21 0x1 >;     /* in zephyr\dts\arm\nordic\nrf52840.dtsi:456 */
			status = "disabled";           /* in zephyr\dts\arm\nordic\nrf52840.dtsi:457 */
			#pwm-cells = < 0x3 >;          /* in zephyr\dts\arm\nordic\nrf52840.dtsi:458 */
		};

		/* node '/soc/pwm@40022000' defined in zephyr\dts\arm\nordic\nrf52840.dtsi:461 */
		pwm2: pwm@40022000 {
			compatible = "nordic,nrf-pwm"; /* in zephyr\dts\arm\nordic\nrf52840.dtsi:462 */
			reg = < 0x40022000 0x1000 >;   /* in zephyr\dts\arm\nordic\nrf52840.dtsi:463 */
			interrupts = < 0x22 0x1 >;     /* in zephyr\dts\arm\nordic\nrf52840.dtsi:464 */
			status = "disabled";           /* in zephyr\dts\arm\nordic\nrf52840.dtsi:465 */
			#pwm-cells = < 0x3 >;          /* in zephyr\dts\arm\nordic\nrf52840.dtsi:466 */
		};

		/* node '/soc/spi@40023000' defined in zephyr\dts\arm\nordic\nrf52840.dtsi:469 */
		spi2: spi@40023000 {
			#address-cells = < 0x1 >;       /* in zephyr\dts\arm\nordic\nrf52840.dtsi:478 */
			#size-cells = < 0x0 >;          /* in zephyr\dts\arm\nordic\nrf52840.dtsi:479 */
			reg = < 0x40023000 0x1000 >;    /* in zephyr\dts\arm\nordic\nrf52840.dtsi:480 */
			interrupts = < 0x23 0x1 >;      /* in zephyr\dts\arm\nordic\nrf52840.dtsi:481 */
			max-frequency = < 0x7a1200 >;   /* in zephyr\dts\arm\nordic\nrf52840.dtsi:482 */
			easydma-maxcnt-bits = < 0x10 >; /* in zephyr\dts\arm\nordic\nrf52840.dtsi:483 */
			compatible = "nordic,nrf-spi";  /* in zephyr\boards\nordic\nrf52840dk\nrf52840dk_nrf52840.dts:243 */
			status = "disabled";            /* in zephyr\boards\nordic\nrf52840dk\nrf52840dk_nrf52840.dts:244 */
			pinctrl-0 = < &spi2_default >;  /* in zephyr\boards\nordic\nrf52840dk\nrf52840dk_nrf52840.dts:245 */
			pinctrl-1 = < &spi2_sleep >;    /* in zephyr\boards\nordic\nrf52840dk\nrf52840dk_nrf52840.dts:246 */
			pinctrl-names = "default",
			                "sleep";        /* in zephyr\boards\nordic\nrf52840dk\nrf52840dk_nrf52840.dts:247 */
		};

		/* node '/soc/rtc@40024000' defined in zephyr\dts\arm\nordic\nrf52840.dtsi:487 */
		rtc2: rtc@40024000 {
			compatible = "nordic,nrf-rtc"; /* in zephyr\dts\arm\nordic\nrf52840.dtsi:488 */
			reg = < 0x40024000 0x1000 >;   /* in zephyr\dts\arm\nordic\nrf52840.dtsi:489 */
			cc-num = < 0x4 >;              /* in zephyr\dts\arm\nordic\nrf52840.dtsi:490 */
			interrupts = < 0x24 0x1 >;     /* in zephyr\dts\arm\nordic\nrf52840.dtsi:491 */
			status = "disabled";           /* in zephyr\dts\arm\nordic\nrf52840.dtsi:492 */
			clock-frequency = < 0x8000 >;  /* in zephyr\dts\arm\nordic\nrf52840.dtsi:493 */
			prescaler = < 0x1 >;           /* in zephyr\dts\arm\nordic\nrf52840.dtsi:494 */
		};

		/* node '/soc/i2s@40025000' defined in zephyr\dts\arm\nordic\nrf52840.dtsi:497 */
		i2s0: i2s@40025000 {
			compatible = "nordic,nrf-i2s"; /* in zephyr\dts\arm\nordic\nrf52840.dtsi:498 */
			#address-cells = < 0x1 >;      /* in zephyr\dts\arm\nordic\nrf52840.dtsi:499 */
			#size-cells = < 0x0 >;         /* in zephyr\dts\arm\nordic\nrf52840.dtsi:500 */
			reg = < 0x40025000 0x1000 >;   /* in zephyr\dts\arm\nordic\nrf52840.dtsi:501 */
			interrupts = < 0x25 0x1 >;     /* in zephyr\dts\arm\nordic\nrf52840.dtsi:502 */
			status = "disabled";           /* in zephyr\dts\arm\nordic\nrf52840.dtsi:503 */
		};

		/* node '/soc/usbd@40027000' defined in zephyr\dts\arm\nordic\nrf52840.dtsi:506 */
		usbd: zephyr_udc0: usbd@40027000 {
			reg = < 0x40027000 0x1000 >;    /* in zephyr\dts\arm\nordic\nrf52840.dtsi:508 */
			interrupts = < 0x27 0x1 >;      /* in zephyr\dts\arm\nordic\nrf52840.dtsi:509 */
			num-bidir-endpoints = < 0x1 >;  /* in zephyr\dts\arm\nordic\nrf52840.dtsi:510 */
			num-in-endpoints = < 0x7 >;     /* in zephyr\dts\arm\nordic\nrf52840.dtsi:511 */
			num-out-endpoints = < 0x7 >;    /* in zephyr\dts\arm\nordic\nrf52840.dtsi:512 */
			num-isoin-endpoints = < 0x1 >;  /* in zephyr\dts\arm\nordic\nrf52840.dtsi:513 */
			num-isoout-endpoints = < 0x1 >; /* in zephyr\dts\arm\nordic\nrf52840.dtsi:514 */
			compatible = "nordic,nrf-usbd"; /* in zephyr\boards\nordic\nrf52840dk\nrf52840dk_nrf52840.dts:289 */
			status = "okay";                /* in zephyr\boards\nordic\nrf52840dk\nrf52840dk_nrf52840.dts:290 */
		};

		/* node '/soc/uart@40028000' defined in zephyr\dts\arm\nordic\nrf52840.dtsi:518 */
		uart1: arduino_serial: uart@40028000 {
			compatible = "nordic,nrf-uarte"; /* in zephyr\dts\arm\nordic\nrf52840.dtsi:519 */
			reg = < 0x40028000 0x1000 >;     /* in zephyr\dts\arm\nordic\nrf52840.dtsi:520 */
			interrupts = < 0x28 0x1 >;       /* in zephyr\dts\arm\nordic\nrf52840.dtsi:521 */
			current-speed = < 0x1c200 >;     /* in zephyr\boards\nordic\nrf52840dk\nrf52840dk_nrf52840.dts:195 */
			pinctrl-0 = < &uart1_default >;  /* in zephyr\boards\nordic\nrf52840dk\nrf52840dk_nrf52840.dts:196 */
			pinctrl-1 = < &uart1_sleep >;    /* in zephyr\boards\nordic\nrf52840dk\nrf52840dk_nrf52840.dts:197 */
			pinctrl-names = "default",
			                "sleep";         /* in zephyr\boards\nordic\nrf52840dk\nrf52840dk_nrf52840.dts:198 */
			status = "disabled";             /* in ..\..\spl\zephyr-dw3000-examples\dw3000-decadriver\zephyr\boards\shields\qorvo_dws3000\boards\nrf52840dk_nrf52840.overlay:6 */
		};

		/* node '/soc/qspi@40029000' defined in zephyr\dts\arm\nordic\nrf52840.dtsi:525 */
		qspi: qspi@40029000 {
			compatible = "nordic,nrf-qspi"; /* in zephyr\dts\arm\nordic\nrf52840.dtsi:526 */
			#address-cells = < 0x1 >;       /* in zephyr\dts\arm\nordic\nrf52840.dtsi:527 */
			#size-cells = < 0x0 >;          /* in zephyr\dts\arm\nordic\nrf52840.dtsi:528 */
			reg = < 0x40029000 0x1000 >,
			      < 0x12000000 0x8000000 >; /* in zephyr\dts\arm\nordic\nrf52840.dtsi:529 */
			reg-names = "qspi",
			            "qspi_mm";          /* in zephyr\dts\arm\nordic\nrf52840.dtsi:530 */
			interrupts = < 0x29 0x1 >;      /* in zephyr\dts\arm\nordic\nrf52840.dtsi:531 */
			status = "okay";                /* in zephyr\boards\nordic\nrf52840dk\nrf52840dk_nrf52840.dts:251 */
			pinctrl-0 = < &qspi_default >;  /* in zephyr\boards\nordic\nrf52840dk\nrf52840dk_nrf52840.dts:252 */
			pinctrl-1 = < &qspi_sleep >;    /* in zephyr\boards\nordic\nrf52840dk\nrf52840dk_nrf52840.dts:253 */
			pinctrl-names = "default",
			                "sleep";        /* in zephyr\boards\nordic\nrf52840dk\nrf52840dk_nrf52840.dts:254 */

			/* node '/soc/qspi@40029000/mx25r6435f@0' defined in zephyr\boards\nordic\nrf52840dk\nrf52840dk_nrf52840.dts:256 */
			mx25r64: mx25r6435f@0 {
				compatible = "nordic,qspi-nor";                                                               /* in zephyr\boards\nordic\nrf52840dk\nrf52840dk_nrf52840.dts:257 */
				reg = < 0x0 >;                                                                                /* in zephyr\boards\nordic\nrf52840dk\nrf52840dk_nrf52840.dts:258 */
				writeoc = "pp4io";                                                                            /* in zephyr\boards\nordic\nrf52840dk\nrf52840dk_nrf52840.dts:260 */
				readoc = "read4io";                                                                           /* in zephyr\boards\nordic\nrf52840dk\nrf52840dk_nrf52840.dts:262 */
				sck-frequency = < 0x7a1200 >;                                                                 /* in zephyr\boards\nordic\nrf52840dk\nrf52840dk_nrf52840.dts:263 */
				jedec-id = [ C2 28 17 ];                                                                      /* in zephyr\boards\nordic\nrf52840dk\nrf52840dk_nrf52840.dts:264 */
				sfdp-bfp = [ E5 20 F1 FF FF FF FF 03 44 EB 08 6B 08 3B 04 BB EE FF FF FF FF FF 00 FF FF FF 00
				             FF 0C 20 0F 52 10 D8 00 FF 23 72 F5 00 82 ED 04 CC 44 83 68 44 30 B0 30 B0 F7 C4
				             D5 5C 00 BE 29 FF F0 D0 FF FF ];                                                 /* in zephyr\boards\nordic\nrf52840dk\nrf52840dk_nrf52840.dts:265 */
				size = < 0x4000000 >;                                                                         /* in zephyr\boards\nordic\nrf52840dk\nrf52840dk_nrf52840.dts:269 */
				has-dpd;                                                                                      /* in zephyr\boards\nordic\nrf52840dk\nrf52840dk_nrf52840.dts:270 */
				t-enter-dpd = < 0x2710 >;                                                                     /* in zephyr\boards\nordic\nrf52840dk\nrf52840dk_nrf52840.dts:271 */
				t-exit-dpd = < 0x88b8 >;                                                                      /* in zephyr\boards\nordic\nrf52840dk\nrf52840dk_nrf52840.dts:272 */
			};
		};

		/* node '/soc/pwm@4002d000' defined in zephyr\dts\arm\nordic\nrf52840.dtsi:535 */
		pwm3: pwm@4002d000 {
			compatible = "nordic,nrf-pwm"; /* in zephyr\dts\arm\nordic\nrf52840.dtsi:536 */
			reg = < 0x4002d000 0x1000 >;   /* in zephyr\dts\arm\nordic\nrf52840.dtsi:537 */
			interrupts = < 0x2d 0x1 >;     /* in zephyr\dts\arm\nordic\nrf52840.dtsi:538 */
			status = "disabled";           /* in zephyr\dts\arm\nordic\nrf52840.dtsi:539 */
			#pwm-cells = < 0x3 >;          /* in zephyr\dts\arm\nordic\nrf52840.dtsi:540 */
		};

		/* node '/soc/spi@4002f000' defined in zephyr\dts\arm\nordic\nrf52840.dtsi:543 */
		spi3: arduino_spi: spi@4002f000 {
			compatible = "nordic,nrf-spim";          /* in zephyr\dts\arm\nordic\nrf52840.dtsi:544 */
			#address-cells = < 0x1 >;                /* in zephyr\dts\arm\nordic\nrf52840.dtsi:545 */
			#size-cells = < 0x0 >;                   /* in zephyr\dts\arm\nordic\nrf52840.dtsi:546 */
			reg = < 0x4002f000 0x1000 >;             /* in zephyr\dts\arm\nordic\nrf52840.dtsi:547 */
			interrupts = < 0x2f 0x1 >;               /* in zephyr\dts\arm\nordic\nrf52840.dtsi:548 */
			max-frequency = < 0x1e84800 >;           /* in zephyr\dts\arm\nordic\nrf52840.dtsi:549 */
			easydma-maxcnt-bits = < 0x10 >;          /* in zephyr\dts\arm\nordic\nrf52840.dtsi:550 */
			rx-delay-supported;                      /* in zephyr\dts\arm\nordic\nrf52840.dtsi:551 */
			rx-delay = < 0x2 >;                      /* in zephyr\dts\arm\nordic\nrf52840.dtsi:552 */
			pinctrl-0 = < &spi3_default >;           /* in zephyr\boards\nordic\nrf52840dk\nrf52840dk_nrf52840.dts:279 */
			pinctrl-1 = < &spi3_sleep >;             /* in zephyr\boards\nordic\nrf52840dk\nrf52840dk_nrf52840.dts:280 */
			pinctrl-names = "default",
			                "sleep";                 /* in zephyr\boards\nordic\nrf52840dk\nrf52840dk_nrf52840.dts:281 */
			status = "okay";                         /* in ..\..\spl\zephyr-dw3000-examples\dw3000-decadriver\zephyr\boards\shields\qorvo_dws3000\qorvo_dws3000.overlay:8 */
			cs-gpios = < &arduino_header 0x10 0x1 >; /* in ..\..\spl\zephyr-dw3000-examples\dw3000-decadriver\zephyr\boards\shields\qorvo_dws3000\qorvo_dws3000.overlay:9 */

			/* node '/soc/spi@4002f000/dws3000@0' defined in ..\..\spl\zephyr-dw3000-examples\dw3000-decadriver\zephyr\boards\shields\qorvo_dws3000\qorvo_dws3000.overlay:11 */
			dws3000@0 {
				compatible = "decawave,dw3000";              /* in ..\..\spl\zephyr-dw3000-examples\dw3000-decadriver\zephyr\boards\shields\qorvo_dws3000\qorvo_dws3000.overlay:12 */
				label = "DWS3000";                           /* in ..\..\spl\zephyr-dw3000-examples\dw3000-decadriver\zephyr\boards\shields\qorvo_dws3000\qorvo_dws3000.overlay:13 */
				spi-max-frequency = < 0xf4240 >;             /* in ..\..\spl\zephyr-dw3000-examples\dw3000-decadriver\zephyr\boards\shields\qorvo_dws3000\qorvo_dws3000.overlay:14 */
				reg = < 0x0 >;                               /* in ..\..\spl\zephyr-dw3000-examples\dw3000-decadriver\zephyr\boards\shields\qorvo_dws3000\qorvo_dws3000.overlay:15 */
				wakeup-gpios = < &arduino_header 0xf 0x0 >;  /* in ..\..\spl\zephyr-dw3000-examples\dw3000-decadriver\zephyr\boards\shields\qorvo_dws3000\qorvo_dws3000.overlay:16 */
				irq-gpios = < &arduino_header 0xe 0x0 >;     /* in ..\..\spl\zephyr-dw3000-examples\dw3000-decadriver\zephyr\boards\shields\qorvo_dws3000\qorvo_dws3000.overlay:17 */
				reset-gpios = < &arduino_header 0xd 0x1 >;   /* in ..\..\spl\zephyr-dw3000-examples\dw3000-decadriver\zephyr\boards\shields\qorvo_dws3000\qorvo_dws3000.overlay:18 */
				spi-pol-gpios = < &arduino_header 0x7 0x1 >; /* in ..\..\spl\zephyr-dw3000-examples\dw3000-decadriver\zephyr\boards\shields\qorvo_dws3000\qorvo_dws3000.overlay:19 */
				spi-pha-gpios = < &arduino_header 0x6 0x1 >; /* in ..\..\spl\zephyr-dw3000-examples\dw3000-decadriver\zephyr\boards\shields\qorvo_dws3000\qorvo_dws3000.overlay:20 */
			};
		};

		/* node '/soc/gpio@50000000' defined in zephyr\dts\arm\nordic\nrf52840.dtsi:556 */
		gpio0: gpio@50000000 {
			compatible = "nordic,nrf-gpio";              /* in zephyr\dts\arm\nordic\nrf52840.dtsi:557 */
			gpio-controller;                             /* in zephyr\dts\arm\nordic\nrf52840.dtsi:558 */
			reg = < 0x50000000 0x200 0x50000500 0x300 >; /* in zephyr\dts\arm\nordic\nrf52840.dtsi:559 */
			#gpio-cells = < 0x2 >;                       /* in zephyr\dts\arm\nordic\nrf52840.dtsi:561 */
			port = < 0x0 >;                              /* in zephyr\dts\arm\nordic\nrf52840.dtsi:563 */
			gpiote-instance = < &gpiote >;               /* in zephyr\dts\arm\nordic\nrf52840.dtsi:564 */
			status = "okay";                             /* in zephyr\boards\nordic\nrf52840dk\nrf52840dk_nrf52840.dts:170 */
			gpio-reserved-ranges = < 0x0 0x2 >,
			                       < 0x6 0x1 >,
			                       < 0x8 0x3 >,
			                       < 0x11 0x7 >;         /* in zephyr\boards\nordic\nrf52840dk\nrf52840dk_nrf52840.dts:171 */
			gpio-line-names = "XL1",
			                  "XL2",
			                  "AREF",
			                  "A0",
			                  "A1",
			                  "RTS",
			                  "TXD",
			                  "CTS",
			                  "RXD",
			                  "NFC1",
			                  "NFC2",
			                  "BUTTON1",
			                  "BUTTON2",
			                  "LED1",
			                  "LED2",
			                  "LED3",
			                  "LED4",
			                  "QSPI CS",
			                  "RESET",
			                  "QSPI CLK",
			                  "QSPI DIO0",
			                  "QSPI DIO1",
			                  "QSPI DIO2",
			                  "QSPI DIO3",
			                  "BUTTON3",
			                  "BUTTON4",
			                  "SDA",
			                  "SCL",
			                  "A2",
			                  "A3",
			                  "A4",
			                  "A5";                      /* in zephyr\boards\nordic\nrf52840dk\nrf52840dk_nrf52840.dts:172 */
			phandle = < 0x19 >;                          /* in zephyr\boards\nordic\nrf52840dk\nrf52840dk_nrf52840.dts:32 */
		};

		/* node '/soc/gpio@50000300' defined in zephyr\dts\arm\nordic\nrf52840.dtsi:567 */
		gpio1: gpio@50000300 {
			compatible = "nordic,nrf-gpio";              /* in zephyr\dts\arm\nordic\nrf52840.dtsi:568 */
			gpio-controller;                             /* in zephyr\dts\arm\nordic\nrf52840.dtsi:569 */
			reg = < 0x50000300 0x200 0x50000800 0x300 >; /* in zephyr\dts\arm\nordic\nrf52840.dtsi:570 */
			#gpio-cells = < 0x2 >;                       /* in zephyr\dts\arm\nordic\nrf52840.dtsi:572 */
			ngpios = < 0x10 >;                           /* in zephyr\dts\arm\nordic\nrf52840.dtsi:573 */
			port = < 0x1 >;                              /* in zephyr\dts\arm\nordic\nrf52840.dtsi:575 */
			gpiote-instance = < &gpiote >;               /* in zephyr\dts\arm\nordic\nrf52840.dtsi:576 */
			status = "okay";                             /* in zephyr\boards\nordic\nrf52840dk\nrf52840dk_nrf52840.dts:180 */
			gpio-line-names = "",
			                  "D0",
			                  "D1",
			                  "D2",
			                  "D3",
			                  "D4",
			                  "D5",
			                  "D6",
			                  "D7",
			                  "",
			                  "D8",
			                  "D9",
			                  "D10",
			                  "D11",
			                  "D12",
			                  "D13";                     /* in zephyr\boards\nordic\nrf52840dk\nrf52840dk_nrf52840.dts:181 */
			phandle = < 0x1b >;                          /* in zephyr\boards\nordic\nrf52840dk\nrf52840dk_nrf52840.dts:93 */
		};

		/* node '/soc/crypto@5002a000' defined in zephyr\dts\arm\nordic\nrf52840.dtsi:579 */
		cryptocell: crypto@5002a000 {
			compatible = "arm,cryptocell-310"; /* in zephyr\dts\arm\nordic\nrf52840.dtsi:580 */
			reg = < 0x5002a000 0x1000 >,
			      < 0x5002b000 0x1000 >;       /* in zephyr\dts\arm\nordic\nrf52840.dtsi:581 */
			reg-names = "wrapper",
			            "core";                /* in zephyr\dts\arm\nordic\nrf52840.dtsi:582 */
			interrupts = < 0x2a 0x1 >;         /* in zephyr\dts\arm\nordic\nrf52840.dtsi:583 */
			status = "okay";                   /* in zephyr\dts\arm\nordic\nrf52840.dtsi:584 */
		};
	};

	/* node '/pin-controller' defined in zephyr\dts\vendor\nordic\nrf_common.dtsi:26 */
	pinctrl: pin-controller {
		compatible = "nordic,nrf-pinctrl"; /* in zephyr\dts\vendor\nordic\nrf_common.dtsi:31 */

		/* node '/pin-controller/uart0_default' defined in zephyr\boards\nordic\nrf52840dk\nrf52840dk_nrf52840-pinctrl.dtsi:7 */
		uart0_default: uart0_default {
			phandle = < 0x2 >; /* in zephyr\boards\nordic\nrf52840dk\nrf52840dk_nrf52840.dts:189 */

			/* node '/pin-controller/uart0_default/group1' defined in zephyr\boards\nordic\nrf52840dk\nrf52840dk_nrf52840-pinctrl.dtsi:8 */
			group1 {
				psels = < 0x6 >,
				        < 0x2000005 >; /* in zephyr\boards\nordic\nrf52840dk\nrf52840dk_nrf52840-pinctrl.dtsi:9 */
			};

			/* node '/pin-controller/uart0_default/group2' defined in zephyr\boards\nordic\nrf52840dk\nrf52840dk_nrf52840-pinctrl.dtsi:13 */
			group2 {
				psels = < 0x1000008 >,
				        < 0x3000007 >; /* in zephyr\boards\nordic\nrf52840dk\nrf52840dk_nrf52840-pinctrl.dtsi:14 */
				bias-pull-up;          /* in zephyr\boards\nordic\nrf52840dk\nrf52840dk_nrf52840-pinctrl.dtsi:16 */
			};
		};

		/* node '/pin-controller/uart0_sleep' defined in zephyr\boards\nordic\nrf52840dk\nrf52840dk_nrf52840-pinctrl.dtsi:20 */
		uart0_sleep: uart0_sleep {
			phandle = < 0x3 >; /* in zephyr\boards\nordic\nrf52840dk\nrf52840dk_nrf52840.dts:190 */

			/* node '/pin-controller/uart0_sleep/group1' defined in zephyr\boards\nordic\nrf52840dk\nrf52840dk_nrf52840-pinctrl.dtsi:21 */
			group1 {
				psels = < 0x1000008 >,
				        < 0x2000005 >,
				        < 0x3000007 >; /* in zephyr\boards\nordic\nrf52840dk\nrf52840dk_nrf52840-pinctrl.dtsi:22 */
				low-power-enable;      /* in zephyr\boards\nordic\nrf52840dk\nrf52840dk_nrf52840-pinctrl.dtsi:25 */
			};

			/* node '/pin-controller/uart0_sleep/group2' defined in zephyr\boards\nordic\nrf52840dk\nrf52840dk_nrf52840-pinctrl.dtsi:28 */
			group2 {
				psels = < 0x6 >;  /* in zephyr\boards\nordic\nrf52840dk\nrf52840dk_nrf52840-pinctrl.dtsi:29 */
				low-power-enable; /* in zephyr\boards\nordic\nrf52840dk\nrf52840dk_nrf52840-pinctrl.dtsi:30 */
				bias-pull-up;     /* in zephyr\boards\nordic\nrf52840dk\nrf52840dk_nrf52840-pinctrl.dtsi:31 */
			};
		};

		/* node '/pin-controller/uart1_default' defined in zephyr\boards\nordic\nrf52840dk\nrf52840dk_nrf52840-pinctrl.dtsi:35 */
		uart1_default: uart1_default {
			phandle = < 0x10 >; /* in zephyr\boards\nordic\nrf52840dk\nrf52840dk_nrf52840.dts:196 */

			/* node '/pin-controller/uart1_default/group1' defined in zephyr\boards\nordic\nrf52840dk\nrf52840dk_nrf52840-pinctrl.dtsi:36 */
			group1 {
				psels = < 0x1000021 >; /* in zephyr\boards\nordic\nrf52840dk\nrf52840dk_nrf52840-pinctrl.dtsi:37 */
				bias-pull-up;          /* in zephyr\boards\nordic\nrf52840dk\nrf52840dk_nrf52840-pinctrl.dtsi:38 */
			};

			/* node '/pin-controller/uart1_default/group2' defined in zephyr\boards\nordic\nrf52840dk\nrf52840dk_nrf52840-pinctrl.dtsi:41 */
			group2 {
				psels = < 0x22 >; /* in zephyr\boards\nordic\nrf52840dk\nrf52840dk_nrf52840-pinctrl.dtsi:42 */
			};
		};

		/* node '/pin-controller/uart1_sleep' defined in zephyr\boards\nordic\nrf52840dk\nrf52840dk_nrf52840-pinctrl.dtsi:46 */
		uart1_sleep: uart1_sleep {
			phandle = < 0x11 >; /* in zephyr\boards\nordic\nrf52840dk\nrf52840dk_nrf52840.dts:197 */

			/* node '/pin-controller/uart1_sleep/group1' defined in zephyr\boards\nordic\nrf52840dk\nrf52840dk_nrf52840-pinctrl.dtsi:47 */
			group1 {
				psels = < 0x1000021 >,
				        < 0x22 >;      /* in zephyr\boards\nordic\nrf52840dk\nrf52840dk_nrf52840-pinctrl.dtsi:48 */
				low-power-enable;      /* in zephyr\boards\nordic\nrf52840dk\nrf52840dk_nrf52840-pinctrl.dtsi:50 */
			};
		};

		/* node '/pin-controller/i2c0_default' defined in zephyr\boards\nordic\nrf52840dk\nrf52840dk_nrf52840-pinctrl.dtsi:54 */
		i2c0_default: i2c0_default {
			phandle = < 0x4 >; /* in zephyr\boards\nordic\nrf52840dk\nrf52840dk_nrf52840.dts:204 */

			/* node '/pin-controller/i2c0_default/group1' defined in zephyr\boards\nordic\nrf52840dk\nrf52840dk_nrf52840-pinctrl.dtsi:55 */
			group1 {
				psels = < 0xc00001a >,
				        < 0xb00001b >; /* in zephyr\boards\nordic\nrf52840dk\nrf52840dk_nrf52840-pinctrl.dtsi:56 */
			};
		};

		/* node '/pin-controller/i2c0_sleep' defined in zephyr\boards\nordic\nrf52840dk\nrf52840dk_nrf52840-pinctrl.dtsi:61 */
		i2c0_sleep: i2c0_sleep {
			phandle = < 0x5 >; /* in zephyr\boards\nordic\nrf52840dk\nrf52840dk_nrf52840.dts:205 */

			/* node '/pin-controller/i2c0_sleep/group1' defined in zephyr\boards\nordic\nrf52840dk\nrf52840dk_nrf52840-pinctrl.dtsi:62 */
			group1 {
				psels = < 0xc00001a >,
				        < 0xb00001b >; /* in zephyr\boards\nordic\nrf52840dk\nrf52840dk_nrf52840-pinctrl.dtsi:63 */
				low-power-enable;      /* in zephyr\boards\nordic\nrf52840dk\nrf52840dk_nrf52840-pinctrl.dtsi:65 */
			};
		};

		/* node '/pin-controller/i2c1_default' defined in zephyr\boards\nordic\nrf52840dk\nrf52840dk_nrf52840-pinctrl.dtsi:69 */
		i2c1_default: i2c1_default {
			phandle = < 0x8 >; /* in zephyr\boards\nordic\nrf52840dk\nrf52840dk_nrf52840.dts:213 */

			/* node '/pin-controller/i2c1_default/group1' defined in zephyr\boards\nordic\nrf52840dk\nrf52840dk_nrf52840-pinctrl.dtsi:70 */
			group1 {
				psels = < 0xc00001e >,
				        < 0xb00001f >; /* in zephyr\boards\nordic\nrf52840dk\nrf52840dk_nrf52840-pinctrl.dtsi:71 */
			};
		};

		/* node '/pin-controller/i2c1_sleep' defined in zephyr\boards\nordic\nrf52840dk\nrf52840dk_nrf52840-pinctrl.dtsi:76 */
		i2c1_sleep: i2c1_sleep {
			phandle = < 0x9 >; /* in zephyr\boards\nordic\nrf52840dk\nrf52840dk_nrf52840.dts:214 */

			/* node '/pin-controller/i2c1_sleep/group1' defined in zephyr\boards\nordic\nrf52840dk\nrf52840dk_nrf52840-pinctrl.dtsi:77 */
			group1 {
				psels = < 0xc00001e >,
				        < 0xb00001f >; /* in zephyr\boards\nordic\nrf52840dk\nrf52840dk_nrf52840-pinctrl.dtsi:78 */
				low-power-enable;      /* in zephyr\boards\nordic\nrf52840dk\nrf52840dk_nrf52840-pinctrl.dtsi:80 */
			};
		};

		/* node '/pin-controller/pwm0_default' defined in zephyr\boards\nordic\nrf52840dk\nrf52840dk_nrf52840-pinctrl.dtsi:84 */
		pwm0_default: pwm0_default {
			phandle = < 0xc >; /* in zephyr\boards\nordic\nrf52840dk\nrf52840dk_nrf52840.dts:220 */

			/* node '/pin-controller/pwm0_default/group1' defined in zephyr\boards\nordic\nrf52840dk\nrf52840dk_nrf52840-pinctrl.dtsi:85 */
			group1 {
				psels = < 0x1600000d >; /* in zephyr\boards\nordic\nrf52840dk\nrf52840dk_nrf52840-pinctrl.dtsi:86 */
				nordic,invert;          /* in zephyr\boards\nordic\nrf52840dk\nrf52840dk_nrf52840-pinctrl.dtsi:87 */
			};
		};

		/* node '/pin-controller/pwm0_sleep' defined in zephyr\boards\nordic\nrf52840dk\nrf52840dk_nrf52840-pinctrl.dtsi:91 */
		pwm0_sleep: pwm0_sleep {
			phandle = < 0xd >; /* in zephyr\boards\nordic\nrf52840dk\nrf52840dk_nrf52840.dts:221 */

			/* node '/pin-controller/pwm0_sleep/group1' defined in zephyr\boards\nordic\nrf52840dk\nrf52840dk_nrf52840-pinctrl.dtsi:92 */
			group1 {
				psels = < 0x1600000d >; /* in zephyr\boards\nordic\nrf52840dk\nrf52840dk_nrf52840-pinctrl.dtsi:93 */
				low-power-enable;       /* in zephyr\boards\nordic\nrf52840dk\nrf52840dk_nrf52840-pinctrl.dtsi:94 */
			};
		};

		/* node '/pin-controller/spi0_default' defined in zephyr\boards\nordic\nrf52840dk\nrf52840dk_nrf52840-pinctrl.dtsi:98 */
		spi0_default: spi0_default {
			phandle = < 0x6 >; /* in zephyr\boards\nordic\nrf52840dk\nrf52840dk_nrf52840.dts:229 */

			/* node '/pin-controller/spi0_default/group1' defined in zephyr\boards\nordic\nrf52840dk\nrf52840dk_nrf52840-pinctrl.dtsi:99 */
			group1 {
				psels = < 0x400001b >,
				        < 0x500001a >,
				        < 0x600001d >; /* in zephyr\boards\nordic\nrf52840dk\nrf52840dk_nrf52840-pinctrl.dtsi:100 */
			};
		};

		/* node '/pin-controller/spi0_sleep' defined in zephyr\boards\nordic\nrf52840dk\nrf52840dk_nrf52840-pinctrl.dtsi:106 */
		spi0_sleep: spi0_sleep {
			phandle = < 0x7 >; /* in zephyr\boards\nordic\nrf52840dk\nrf52840dk_nrf52840.dts:230 */

			/* node '/pin-controller/spi0_sleep/group1' defined in zephyr\boards\nordic\nrf52840dk\nrf52840dk_nrf52840-pinctrl.dtsi:107 */
			group1 {
				psels = < 0x400001b >,
				        < 0x500001a >,
				        < 0x600001d >; /* in zephyr\boards\nordic\nrf52840dk\nrf52840dk_nrf52840-pinctrl.dtsi:108 */
				low-power-enable;      /* in zephyr\boards\nordic\nrf52840dk\nrf52840dk_nrf52840-pinctrl.dtsi:111 */
			};
		};

		/* node '/pin-controller/spi1_default' defined in zephyr\boards\nordic\nrf52840dk\nrf52840dk_nrf52840-pinctrl.dtsi:115 */
		spi1_default: spi1_default {
			phandle = < 0xa >; /* in zephyr\boards\nordic\nrf52840dk\nrf52840dk_nrf52840.dts:237 */

			/* node '/pin-controller/spi1_default/group1' defined in zephyr\boards\nordic\nrf52840dk\nrf52840dk_nrf52840-pinctrl.dtsi:116 */
			group1 {
				psels = < 0x400001f >,
				        < 0x500001e >,
				        < 0x6000028 >; /* in zephyr\boards\nordic\nrf52840dk\nrf52840dk_nrf52840-pinctrl.dtsi:117 */
			};
		};

		/* node '/pin-controller/spi1_sleep' defined in zephyr\boards\nordic\nrf52840dk\nrf52840dk_nrf52840-pinctrl.dtsi:123 */
		spi1_sleep: spi1_sleep {
			phandle = < 0xb >; /* in zephyr\boards\nordic\nrf52840dk\nrf52840dk_nrf52840.dts:238 */

			/* node '/pin-controller/spi1_sleep/group1' defined in zephyr\boards\nordic\nrf52840dk\nrf52840dk_nrf52840-pinctrl.dtsi:124 */
			group1 {
				psels = < 0x400001f >,
				        < 0x500001e >,
				        < 0x6000028 >; /* in zephyr\boards\nordic\nrf52840dk\nrf52840dk_nrf52840-pinctrl.dtsi:125 */
				low-power-enable;      /* in zephyr\boards\nordic\nrf52840dk\nrf52840dk_nrf52840-pinctrl.dtsi:128 */
			};
		};

		/* node '/pin-controller/spi2_default' defined in zephyr\boards\nordic\nrf52840dk\nrf52840dk_nrf52840-pinctrl.dtsi:132 */
		spi2_default: spi2_default {
			phandle = < 0xe >; /* in zephyr\boards\nordic\nrf52840dk\nrf52840dk_nrf52840.dts:245 */

			/* node '/pin-controller/spi2_default/group1' defined in zephyr\boards\nordic\nrf52840dk\nrf52840dk_nrf52840-pinctrl.dtsi:133 */
			group1 {
				psels = < 0x4000013 >,
				        < 0x5000014 >,
				        < 0x6000015 >; /* in zephyr\boards\nordic\nrf52840dk\nrf52840dk_nrf52840-pinctrl.dtsi:134 */
			};
		};

		/* node '/pin-controller/spi2_sleep' defined in zephyr\boards\nordic\nrf52840dk\nrf52840dk_nrf52840-pinctrl.dtsi:140 */
		spi2_sleep: spi2_sleep {
			phandle = < 0xf >; /* in zephyr\boards\nordic\nrf52840dk\nrf52840dk_nrf52840.dts:246 */

			/* node '/pin-controller/spi2_sleep/group1' defined in zephyr\boards\nordic\nrf52840dk\nrf52840dk_nrf52840-pinctrl.dtsi:141 */
			group1 {
				psels = < 0x4000013 >,
				        < 0x5000014 >,
				        < 0x6000015 >; /* in zephyr\boards\nordic\nrf52840dk\nrf52840dk_nrf52840-pinctrl.dtsi:142 */
				low-power-enable;      /* in zephyr\boards\nordic\nrf52840dk\nrf52840dk_nrf52840-pinctrl.dtsi:145 */
			};
		};

		/* node '/pin-controller/qspi_default' defined in zephyr\boards\nordic\nrf52840dk\nrf52840dk_nrf52840-pinctrl.dtsi:149 */
		qspi_default: qspi_default {
			phandle = < 0x12 >; /* in zephyr\boards\nordic\nrf52840dk\nrf52840dk_nrf52840.dts:252 */

			/* node '/pin-controller/qspi_default/group1' defined in zephyr\boards\nordic\nrf52840dk\nrf52840dk_nrf52840-pinctrl.dtsi:150 */
			group1 {
				psels = < 0x1d000013 >,
				        < 0x1f000014 >,
				        < 0x20000015 >,
				        < 0x21000016 >,
				        < 0x22000017 >,
				        < 0x1e000011 >;      /* in zephyr\boards\nordic\nrf52840dk\nrf52840dk_nrf52840-pinctrl.dtsi:151 */
				nordic,drive-mode = < 0x3 >; /* in zephyr\boards\nordic\nrf52840dk\nrf52840dk_nrf52840-pinctrl.dtsi:157 */
			};
		};

		/* node '/pin-controller/qspi_sleep' defined in zephyr\boards\nordic\nrf52840dk\nrf52840dk_nrf52840-pinctrl.dtsi:161 */
		qspi_sleep: qspi_sleep {
			phandle = < 0x13 >; /* in zephyr\boards\nordic\nrf52840dk\nrf52840dk_nrf52840.dts:253 */

			/* node '/pin-controller/qspi_sleep/group1' defined in zephyr\boards\nordic\nrf52840dk\nrf52840dk_nrf52840-pinctrl.dtsi:162 */
			group1 {
				psels = < 0x1d000013 >,
				        < 0x1f000014 >,
				        < 0x20000015 >,
				        < 0x21000016 >,
				        < 0x22000017 >; /* in zephyr\boards\nordic\nrf52840dk\nrf52840dk_nrf52840-pinctrl.dtsi:163 */
				low-power-enable;       /* in zephyr\boards\nordic\nrf52840dk\nrf52840dk_nrf52840-pinctrl.dtsi:168 */
			};

			/* node '/pin-controller/qspi_sleep/group2' defined in zephyr\boards\nordic\nrf52840dk\nrf52840dk_nrf52840-pinctrl.dtsi:171 */
			group2 {
				psels = < 0x1e000011 >; /* in zephyr\boards\nordic\nrf52840dk\nrf52840dk_nrf52840-pinctrl.dtsi:172 */
				low-power-enable;       /* in zephyr\boards\nordic\nrf52840dk\nrf52840dk_nrf52840-pinctrl.dtsi:173 */
				bias-pull-up;           /* in zephyr\boards\nordic\nrf52840dk\nrf52840dk_nrf52840-pinctrl.dtsi:174 */
			};
		};

		/* node '/pin-controller/spi3_default' defined in zephyr\boards\nordic\nrf52840dk\nrf52840dk_nrf52840-pinctrl.dtsi:178 */
		spi3_default: spi3_default {
			phandle = < 0x14 >; /* in zephyr\boards\nordic\nrf52840dk\nrf52840dk_nrf52840.dts:279 */

			/* node '/pin-controller/spi3_default/group1' defined in zephyr\boards\nordic\nrf52840dk\nrf52840dk_nrf52840-pinctrl.dtsi:179 */
			group1 {
				psels = < 0x400002f >,
				        < 0x600002e >,
				        < 0x500002d >;       /* in zephyr\boards\nordic\nrf52840dk\nrf52840dk_nrf52840-pinctrl.dtsi:180 */
				nordic,drive-mode = < 0x3 >; /* in zephyr\boards\nordic\nrf52840dk\nrf52840dk_nrf52840-pinctrl.dtsi:183 */
			};
		};

		/* node '/pin-controller/spi3_sleep' defined in zephyr\boards\nordic\nrf52840dk\nrf52840dk_nrf52840-pinctrl.dtsi:187 */
		spi3_sleep: spi3_sleep {
			phandle = < 0x15 >; /* in zephyr\boards\nordic\nrf52840dk\nrf52840dk_nrf52840.dts:280 */

			/* node '/pin-controller/spi3_sleep/group1' defined in zephyr\boards\nordic\nrf52840dk\nrf52840dk_nrf52840-pinctrl.dtsi:188 */
			group1 {
				psels = < 0x400002f >,
				        < 0x600002e >,
				        < 0x500002d >; /* in zephyr\boards\nordic\nrf52840dk\nrf52840dk_nrf52840-pinctrl.dtsi:189 */
				low-power-enable;      /* in zephyr\boards\nordic\nrf52840dk\nrf52840dk_nrf52840-pinctrl.dtsi:192 */
			};
		};
	};

	/* node '/entropy_bt_hci' defined in zephyr\dts\vendor\nordic\nrf_common.dtsi:34 */
	rng_hci: entropy_bt_hci {
		compatible = "zephyr,bt-hci-entropy"; /* in zephyr\dts\vendor\nordic\nrf_common.dtsi:35 */
		status = "disabled";                  /* in zephyr\dts\vendor\nordic\nrf_common.dtsi:36 */
	};

	/* node '/sw-pwm' defined in zephyr\dts\vendor\nordic\nrf_common.dtsi:39 */
	sw_pwm: sw-pwm {
		compatible = "nordic,nrf-sw-pwm"; /* in zephyr\dts\vendor\nordic\nrf_common.dtsi:40 */
		status = "disabled";              /* in zephyr\dts\vendor\nordic\nrf_common.dtsi:41 */
		generator = < &timer1 >;          /* in zephyr\dts\vendor\nordic\nrf_common.dtsi:42 */
		clock-prescaler = < 0x0 >;        /* in zephyr\dts\vendor\nordic\nrf_common.dtsi:43 */
		#pwm-cells = < 0x3 >;             /* in zephyr\dts\vendor\nordic\nrf_common.dtsi:44 */
	};

	/* node '/cpus' defined in zephyr\dts\arm\nordic\nrf52840.dtsi:19 */
	cpus {
		#address-cells = < 0x1 >; /* in zephyr\dts\arm\nordic\nrf52840.dtsi:20 */
		#size-cells = < 0x0 >;    /* in zephyr\dts\arm\nordic\nrf52840.dtsi:21 */

		/* node '/cpus/cpu@0' defined in zephyr\dts\arm\nordic\nrf52840.dtsi:23 */
		cpu@0 {
			device_type = "cpu";           /* in zephyr\dts\arm\nordic\nrf52840.dtsi:24 */
			compatible = "arm,cortex-m4f"; /* in zephyr\dts\arm\nordic\nrf52840.dtsi:25 */
			reg = < 0x0 >;                 /* in zephyr\dts\arm\nordic\nrf52840.dtsi:26 */
			#address-cells = < 0x1 >;      /* in zephyr\dts\arm\nordic\nrf52840.dtsi:27 */
			#size-cells = < 0x1 >;         /* in zephyr\dts\arm\nordic\nrf52840.dtsi:28 */

			/* node '/cpus/cpu@0/itm@e0000000' defined in zephyr\dts\arm\nordic\nrf52840.dtsi:30 */
			itm: itm@e0000000 {
				compatible = "arm,armv7m-itm";     /* in zephyr\dts\arm\nordic\nrf52840.dtsi:31 */
				reg = < 0xe0000000 0x1000 >;       /* in zephyr\dts\arm\nordic\nrf52840.dtsi:32 */
				swo-ref-frequency = < 0x1e84800 >; /* in zephyr\dts\arm\nordic\nrf52840.dtsi:33 */
			};
		};
	};

	/* node '/clocks' defined in zephyr\dts\arm\nordic\nrf52840.dtsi:38 */
	clocks {

		/* node '/clocks/hfxo' defined in zephyr\dts\arm\nordic\nrf52840.dtsi:39 */
		hfxo: hfxo {
			compatible = "nordic,nrf52-hfxo"; /* in zephyr\dts\arm\nordic\nrf52840.dtsi:40 */
			clock-frequency = < 0x3d09000 >;  /* in zephyr\dts\arm\nordic\nrf52840.dtsi:41 */
			startup-time-us = < 0x578 >;      /* in zephyr\dts\arm\nordic\nrf52840.dtsi:42 */
			#clock-cells = < 0x0 >;           /* in zephyr\dts\arm\nordic\nrf52840.dtsi:43 */
		};
	};

	/* node '/leds' defined in zephyr\boards\nordic\nrf52840dk\nrf52840dk_nrf52840.dts:28 */
	leds {
		compatible = "gpio-leds"; /* in zephyr\boards\nordic\nrf52840dk\nrf52840dk_nrf52840.dts:29 */

		/* node '/leds/led_0' defined in zephyr\boards\nordic\nrf52840dk\nrf52840dk_nrf52840.dts:31 */
		led0: led_0 {
			gpios = < &gpio0 0xd 0x1 >; /* in zephyr\boards\nordic\nrf52840dk\nrf52840dk_nrf52840.dts:32 */
			label = "Green LED 0";      /* in zephyr\boards\nordic\nrf52840dk\nrf52840dk_nrf52840.dts:33 */
		};

		/* node '/leds/led_1' defined in zephyr\boards\nordic\nrf52840dk\nrf52840dk_nrf52840.dts:36 */
		led1: led_1 {
			gpios = < &gpio0 0xe 0x1 >; /* in zephyr\boards\nordic\nrf52840dk\nrf52840dk_nrf52840.dts:37 */
			label = "Green LED 1";      /* in zephyr\boards\nordic\nrf52840dk\nrf52840dk_nrf52840.dts:38 */
		};

		/* node '/leds/led_2' defined in zephyr\boards\nordic\nrf52840dk\nrf52840dk_nrf52840.dts:41 */
		led2: led_2 {
			gpios = < &gpio0 0xf 0x1 >; /* in zephyr\boards\nordic\nrf52840dk\nrf52840dk_nrf52840.dts:42 */
			label = "Green LED 2";      /* in zephyr\boards\nordic\nrf52840dk\nrf52840dk_nrf52840.dts:43 */
		};

		/* node '/leds/led_3' defined in zephyr\boards\nordic\nrf52840dk\nrf52840dk_nrf52840.dts:46 */
		led3: led_3 {
			gpios = < &gpio0 0x10 0x1 >; /* in zephyr\boards\nordic\nrf52840dk\nrf52840dk_nrf52840.dts:47 */
			label = "Green LED 3";       /* in zephyr\boards\nordic\nrf52840dk\nrf52840dk_nrf52840.dts:48 */
		};
	};

	/* node '/pwmleds' defined in zephyr\boards\nordic\nrf52840dk\nrf52840dk_nrf52840.dts:52 */
	pwmleds {
		compatible = "pwm-leds"; /* in zephyr\boards\nordic\nrf52840dk\nrf52840dk_nrf52840.dts:53 */

		/* node '/pwmleds/pwm_led_0' defined in zephyr\boards\nordic\nrf52840dk\nrf52840dk_nrf52840.dts:55 */
		pwm_led0: pwm_led_0 {
			pwms = < &pwm0 0x0 0x1312d00 0x1 >; /* in zephyr\boards\nordic\nrf52840dk\nrf52840dk_nrf52840.dts:56 */
		};
	};

	/* node '/buttons' defined in zephyr\boards\nordic\nrf52840dk\nrf52840dk_nrf52840.dts:60 */
	buttons {
		compatible = "gpio-keys"; /* in zephyr\boards\nordic\nrf52840dk\nrf52840dk_nrf52840.dts:61 */

		/* node '/buttons/button_0' defined in zephyr\boards\nordic\nrf52840dk\nrf52840dk_nrf52840.dts:63 */
		button0: button_0 {
			gpios = < &gpio0 0xb 0x11 >;    /* in zephyr\boards\nordic\nrf52840dk\nrf52840dk_nrf52840.dts:64 */
			label = "Push button switch 0"; /* in zephyr\boards\nordic\nrf52840dk\nrf52840dk_nrf52840.dts:65 */
			zephyr,code = < 0xb >;          /* in zephyr\boards\nordic\nrf52840dk\nrf52840dk_nrf52840.dts:66 */
		};

		/* node '/buttons/button_1' defined in zephyr\boards\nordic\nrf52840dk\nrf52840dk_nrf52840.dts:69 */
		button1: button_1 {
			gpios = < &gpio0 0xc 0x11 >;    /* in zephyr\boards\nordic\nrf52840dk\nrf52840dk_nrf52840.dts:70 */
			label = "Push button switch 1"; /* in zephyr\boards\nordic\nrf52840dk\nrf52840dk_nrf52840.dts:71 */
			zephyr,code = < 0x2 >;          /* in zephyr\boards\nordic\nrf52840dk\nrf52840dk_nrf52840.dts:72 */
		};

		/* node '/buttons/button_2' defined in zephyr\boards\nordic\nrf52840dk\nrf52840dk_nrf52840.dts:75 */
		button2: button_2 {
			gpios = < &gpio0 0x18 0x11 >;   /* in zephyr\boards\nordic\nrf52840dk\nrf52840dk_nrf52840.dts:76 */
			label = "Push button switch 2"; /* in zephyr\boards\nordic\nrf52840dk\nrf52840dk_nrf52840.dts:77 */
			zephyr,code = < 0x3 >;          /* in zephyr\boards\nordic\nrf52840dk\nrf52840dk_nrf52840.dts:78 */
		};

		/* node '/buttons/button_3' defined in zephyr\boards\nordic\nrf52840dk\nrf52840dk_nrf52840.dts:81 */
		button3: button_3 {
			gpios = < &gpio0 0x19 0x11 >;   /* in zephyr\boards\nordic\nrf52840dk\nrf52840dk_nrf52840.dts:82 */
			label = "Push button switch 3"; /* in zephyr\boards\nordic\nrf52840dk\nrf52840dk_nrf52840.dts:83 */
			zephyr,code = < 0x4 >;          /* in zephyr\boards\nordic\nrf52840dk\nrf52840dk_nrf52840.dts:84 */
		};
	};

	/* node '/connector' defined in zephyr\boards\nordic\nrf52840dk\nrf52840dk_nrf52840.dts:88 */
	arduino_header: connector {
		compatible = "arduino-header-r3";          /* in zephyr\boards\nordic\nrf52840dk\nrf52840dk_nrf52840.dts:89 */
		#gpio-cells = < 0x2 >;                     /* in zephyr\boards\nordic\nrf52840dk\nrf52840dk_nrf52840.dts:90 */
		gpio-map-mask = < 0xffffffff 0xffffffc0 >; /* in zephyr\boards\nordic\nrf52840dk\nrf52840dk_nrf52840.dts:91 */
		gpio-map-pass-thru = < 0x0 0x3f >;         /* in zephyr\boards\nordic\nrf52840dk\nrf52840dk_nrf52840.dts:92 */
		gpio-map = < 0x0 0x0 &gpio0 0x3 0x0 >,
		           < 0x1 0x0 &gpio0 0x4 0x0 >,
		           < 0x2 0x0 &gpio0 0x1c 0x0 >,
		           < 0x3 0x0 &gpio0 0x1d 0x0 >,
		           < 0x4 0x0 &gpio0 0x1e 0x0 >,
		           < 0x5 0x0 &gpio0 0x1f 0x0 >,
		           < 0x6 0x0 &gpio1 0x1 0x0 >,
		           < 0x7 0x0 &gpio1 0x2 0x0 >,
		           < 0x8 0x0 &gpio1 0x3 0x0 >,
		           < 0x9 0x0 &gpio1 0x4 0x0 >,
		           < 0xa 0x0 &gpio1 0x5 0x0 >,
		           < 0xb 0x0 &gpio1 0x6 0x0 >,
		           < 0xc 0x0 &gpio1 0x7 0x0 >,
		           < 0xd 0x0 &gpio1 0x8 0x0 >,
		           < 0xe 0x0 &gpio1 0xa 0x0 >,
		           < 0xf 0x0 &gpio1 0xb 0x0 >,
		           < 0x10 0x0 &gpio1 0xc 0x0 >,
		           < 0x11 0x0 &gpio1 0xd 0x0 >,
		           < 0x12 0x0 &gpio1 0xe 0x0 >,
		           < 0x13 0x0 &gpio1 0xf 0x0 >,
		           < 0x14 0x0 &gpio0 0x1a 0x0 >,
		           < 0x15 0x0 &gpio0 0x1b 0x0 >;   /* in zephyr\boards\nordic\nrf52840dk\nrf52840dk_nrf52840.dts:93 */
		phandle = < 0x16 >;                        /* in ..\..\spl\zephyr-dw3000-examples\dw3000-decadriver\zephyr\boards\shields\qorvo_dws3000\qorvo_dws3000.overlay:9 */
	};

	/* node '/analog-connector' defined in zephyr\boards\nordic\nrf52840dk\nrf52840dk_nrf52840.dts:117 */
	arduino_adc: analog-connector {
		compatible = "arduino,uno-adc";    /* in zephyr\boards\nordic\nrf52840dk\nrf52840dk_nrf52840.dts:118 */
		#io-channel-cells = < 0x1 >;       /* in zephyr\boards\nordic\nrf52840dk\nrf52840dk_nrf52840.dts:119 */
		io-channel-map = < 0x0 &adc 0x1 >,
		                 < 0x1 &adc 0x2 >,
		                 < 0x2 &adc 0x4 >,
		                 < 0x3 &adc 0x5 >,
		                 < 0x4 &adc 0x6 >,
		                 < 0x5 &adc 0x7 >; /* in zephyr\boards\nordic\nrf52840dk\nrf52840dk_nrf52840.dts:120 */
	};
};
